VERSION ""

NS_ :

BS_:

BU_: VCU BMS DCDC OBC
VAL_TABLE_ CC2_State 1 "DC_Charge" 0 "No_DC_Charge" ;
VAL_TABLE_ DCDCOPERATINGMODE 4 "fault level-2" 3 "fault level-1" 2 "Work" 1 "Standby" 0 "Init" ;

BO_ 344 EAT_158: 8 VCU
 SG_ EAT_CHECKSUM_158 : 59|4@0+ (1,0) [0|15] ""  OBC
 SG_ EAT_ALIVE_COUNTER_158 : 61|2@0+ (1,0) [0|3] ""  OBC
 SG_ EAT_TRANS_SPEED : 39|16@0+ (0.01,0) [0|655.35] ""  OBC

BO_ 2373075255 EAT_158: 8 VCU
 SG_ EAT_CHECKSUM_158 : 59|4@0+ (1,0) [0|15] ""  OBC
 SG_ EAT_ALIVE_COUNTER_158 : 61|2@0+ (1,0) [0|3] ""  OBC
 SG_ EAT_TRANS_SPEED : 39|16@0+ (0.01,0) [0|655.35] ""  OBC

BO_ 2373075256 EAT_158: 8 VCU
 SG_ EAT_CHECKSUM_158 : 59|4@0+ (1,0) [0|15] ""  OBC
 SG_ EAT_ALIVE_COUNTER_158 : 61|2@0+ (1,0) [0|3] ""  OBC
 SG_ EAT_TRANS_SPEED : 39|16@0+ (0.01,0) [0|655.35] ""  OBC

BO_ 2373075257 EAT_158: 8 VCU
 SG_ EAT_CHECKSUM_158 : 59|4@0+ (1,0) [0|15] ""  OBC
 SG_ EAT_ALIVE_COUNTER_158 : 61|2@0+ (1,0) [0|3] ""  OBC
 SG_ EAT_TRANS_SPEED : 39|16@0+ (0.01,0) [0|655.35] ""  OBC

BO_ 2373075258 EAT_158: 8 VCU
 SG_ EAT_CHECKSUM_158 : 59|4@0+ (1,0) [0|15] ""  OBC
 SG_ EAT_ALIVE_COUNTER_158 : 61|2@0+ (1,0) [0|3] ""  OBC
 SG_ EAT_TRANS_SPEED : 39|16@0+ (0.01,0) [0|655.35] ""  OBC

BO_ 2373075259 EAT_158: 8 VCU
 SG_ EAT_CHECKSUM_158 : 59|4@0+ (1,0) [0|15] ""  OBC
 SG_ EAT_ALIVE_COUNTER_158 : 61|2@0+ (1,0) [0|3] ""  OBC
 SG_ EAT_TRANS_SPEED : 39|16@0+ (0.01,0) [0|655.35] ""  OBC

BO_ 2373075260 EAT_158: 8 VCU
 SG_ EAT_CHECKSUM_158 : 59|4@0+ (1,0) [0|15] ""  OBC
 SG_ EAT_ALIVE_COUNTER_158 : 61|2@0+ (1,0) [0|3] ""  OBC
 SG_ EAT_TRANS_SPEED : 39|16@0+ (0.01,0) [0|655.35] ""  OBC

BO_ 2373075261 EAT_158: 8 VCU
 SG_ EAT_CHECKSUM_158 : 59|4@0+ (1,0) [0|15] ""  OBC
 SG_ EAT_ALIVE_COUNTER_158 : 61|2@0+ (1,0) [0|3] ""  OBC
 SG_ EAT_TRANS_SPEED : 39|16@0+ (0.01,0) [0|655.35] ""  OBC

BO_ 2373075262 EAT_158: 8 VCU
 SG_ EAT_CHECKSUM_158 : 59|4@0+ (1,0) [0|15] ""  OBC
 SG_ EAT_ALIVE_COUNTER_158 : 61|2@0+ (1,0) [0|3] ""  OBC
 SG_ EAT_TRANS_SPEED : 39|16@0+ (0.01,0) [0|655.35] ""  OBC

BO_ 2373075263 EAT_158: 8 VCU
 SG_ EAT_CHECKSUM_158 : 59|4@0+ (1,0) [0|15] ""  OBC
 SG_ EAT_ALIVE_COUNTER_158 : 61|2@0+ (1,0) [0|3] ""  OBC
 SG_ EAT_TRANS_SPEED : 39|16@0+ (0.01,0) [0|655.35] ""  OBC

BO_ 2373075264 EAT_158: 8 VCU
 SG_ EAT_CHECKSUM_158 : 59|4@0+ (1,0) [0|15] ""  OBC
 SG_ EAT_ALIVE_COUNTER_158 : 61|2@0+ (1,0) [0|3] ""  OBC
 SG_ EAT_TRANS_SPEED : 39|16@0+ (0.01,0) [0|655.35] ""  OBC

BO_ 2373075265 EAT_158: 8 VCU
 SG_ EAT_CHECKSUM_158 : 59|4@0+ (1,0) [0|15] ""  OBC
 SG_ EAT_ALIVE_COUNTER_158 : 61|2@0+ (1,0) [0|3] ""  OBC
 SG_ EAT_TRANS_SPEED : 39|16@0+ (0.01,0) [0|655.35] ""  OBC

BO_ 2373075266 EAT_158: 8 VCU
 SG_ EAT_CHECKSUM_158 : 59|4@0+ (1,0) [0|15] ""  OBC
 SG_ EAT_ALIVE_COUNTER_158 : 61|2@0+ (1,0) [0|3] ""  OBC
 SG_ EAT_TRANS_SPEED : 39|16@0+ (0.01,0) [0|655.35] ""  OBC

BO_ 2373075267 EAT_158: 8 VCU
 SG_ EAT_CHECKSUM_158 : 59|4@0+ (1,0) [0|15] ""  OBC
 SG_ EAT_ALIVE_COUNTER_158 : 61|2@0+ (1,0) [0|3] ""  OBC
 SG_ EAT_TRANS_SPEED : 39|16@0+ (0.01,0) [0|655.35] ""  OBC

BO_ 2373075268 EAT_158: 8 VCU
 SG_ EAT_CHECKSUM_158 : 59|4@0+ (1,0) [0|15] ""  OBC
 SG_ EAT_ALIVE_COUNTER_158 : 61|2@0+ (1,0) [0|3] ""  OBC
 SG_ EAT_TRANS_SPEED : 39|16@0+ (0.01,0) [0|655.35] ""  OBC

BO_ 2373075269 EAT_158: 8 VCU
 SG_ EAT_CHECKSUM_158 : 59|4@0+ (1,0) [0|15] ""  OBC
 SG_ EAT_ALIVE_COUNTER_158 : 61|2@0+ (1,0) [0|3] ""  OBC
 SG_ EAT_TRANS_SPEED : 39|16@0+ (0.01,0) [0|655.35] ""  OBC

BO_ 2373075270 EAT_158: 8 VCU
 SG_ EAT_CHECKSUM_158 : 59|4@0+ (1,0) [0|15] ""  OBC
 SG_ EAT_ALIVE_COUNTER_158 : 61|2@0+ (1,0) [0|3] ""  OBC
 SG_ EAT_TRANS_SPEED : 39|16@0+ (0.01,0) [0|655.35] ""  OBC

BO_ 2373075271 EAT_158: 8 VCU
 SG_ EAT_CHECKSUM_158 : 59|4@0+ (1,0) [0|15] ""  OBC
 SG_ EAT_ALIVE_COUNTER_158 : 61|2@0+ (1,0) [0|3] ""  OBC
 SG_ EAT_TRANS_SPEED : 39|16@0+ (0.01,0) [0|655.35] ""  OBC

BO_ 2373075272 EAT_158: 8 VCU
 SG_ EAT_CHECKSUM_158 : 59|4@0+ (1,0) [0|15] ""  OBC
 SG_ EAT_ALIVE_COUNTER_158 : 61|2@0+ (1,0) [0|3] ""  OBC
 SG_ EAT_TRANS_SPEED : 39|16@0+ (0.01,0) [0|655.35] ""  OBC

BO_ 2373075273 EAT_158: 8 VCU
 SG_ EAT_CHECKSUM_158 : 59|4@0+ (1,0) [0|15] ""  OBC
 SG_ EAT_ALIVE_COUNTER_158 : 61|2@0+ (1,0) [0|3] ""  OBC
 SG_ EAT_TRANS_SPEED : 39|16@0+ (0.01,0) [0|655.35] ""  OBC

BO_ 2373075274 EAT_158: 8 VCU
 SG_ EAT_CHECKSUM_158 : 59|4@0+ (1,0) [0|15] ""  OBC
 SG_ EAT_ALIVE_COUNTER_158 : 61|2@0+ (1,0) [0|3] ""  OBC
 SG_ EAT_TRANS_SPEED : 39|16@0+ (0.01,0) [0|655.35] ""  OBC

BO_ 2373075275 EAT_158: 8 VCU
 SG_ EAT_CHECKSUM_158 : 59|4@0+ (1,0) [0|15] ""  OBC
 SG_ EAT_ALIVE_COUNTER_158 : 61|2@0+ (1,0) [0|3] ""  OBC
 SG_ EAT_TRANS_SPEED : 39|16@0+ (0.01,0) [0|655.35] ""  OBC

BO_ 2373075276 EAT_158: 8 VCU
 SG_ EAT_CHECKSUM_158 : 59|4@0+ (1,0) [0|15] ""  OBC
 SG_ EAT_ALIVE_COUNTER_158 : 61|2@0+ (1,0) [0|3] ""  OBC
 SG_ EAT_TRANS_SPEED : 39|16@0+ (0.01,0) [0|655.35] ""  OBC

BO_ 2373075277 EAT_158: 8 VCU
 SG_ EAT_CHECKSUM_158 : 59|4@0+ (1,0) [0|15] ""  OBC
 SG_ EAT_ALIVE_COUNTER_158 : 61|2@0+ (1,0) [0|3] ""  OBC
 SG_ EAT_TRANS_SPEED : 39|16@0+ (0.01,0) [0|655.35] ""  OBC

BO_ 2373075278 EAT_158: 8 VCU
 SG_ EAT_CHECKSUM_158 : 59|4@0+ (1,0) [0|15] ""  OBC
 SG_ EAT_ALIVE_COUNTER_158 : 61|2@0+ (1,0) [0|3] ""  OBC
 SG_ EAT_TRANS_SPEED : 39|16@0+ (0.01,0) [0|655.35] ""  OBC

BO_ 2373075279 EAT_158: 8 VCU
 SG_ EAT_CHECKSUM_158 : 59|4@0+ (1,0) [0|15] ""  OBC
 SG_ EAT_ALIVE_COUNTER_158 : 61|2@0+ (1,0) [0|3] ""  OBC
 SG_ EAT_TRANS_SPEED : 39|16@0+ (0.01,0) [0|655.35] ""  OBC

BO_ 2373075280 EAT_158: 8 VCU
 SG_ EAT_CHECKSUM_158 : 59|4@0+ (1,0) [0|15] ""  OBC
 SG_ EAT_ALIVE_COUNTER_158 : 61|2@0+ (1,0) [0|3] ""  OBC
 SG_ EAT_TRANS_SPEED : 39|16@0+ (0.01,0) [0|655.35] ""  OBC

BO_ 2373075281 EAT_158: 8 VCU
 SG_ EAT_CHECKSUM_158 : 59|4@0+ (1,0) [0|15] ""  OBC
 SG_ EAT_ALIVE_COUNTER_158 : 61|2@0+ (1,0) [0|3] ""  OBC
 SG_ EAT_TRANS_SPEED : 39|16@0+ (0.01,0) [0|655.35] ""  OBC

BO_ 2373075282 EAT_158: 8 VCU
 SG_ EAT_CHECKSUM_158 : 59|4@0+ (1,0) [0|15] ""  OBC
 SG_ EAT_ALIVE_COUNTER_158 : 61|2@0+ (1,0) [0|3] ""  OBC
 SG_ EAT_TRANS_SPEED : 39|16@0+ (0.01,0) [0|655.35] ""  OBC

BO_ 2373075283 EAT_158: 8 VCU
 SG_ EAT_CHECKSUM_158 : 59|4@0+ (1,0) [0|15] ""  OBC
 SG_ EAT_ALIVE_COUNTER_158 : 61|2@0+ (1,0) [0|3] ""  OBC
 SG_ EAT_TRANS_SPEED : 39|16@0+ (0.01,0) [0|655.35] ""  OBC

BO_ 2373075284 EAT_158: 8 VCU
 SG_ EAT_CHECKSUM_158 : 59|4@0+ (1,0) [0|15] ""  OBC
 SG_ EAT_ALIVE_COUNTER_158 : 61|2@0+ (1,0) [0|3] ""  OBC
 SG_ EAT_TRANS_SPEED : 39|16@0+ (0.01,0) [0|655.35] ""  OBC

BO_ 2373075285 EAT_158: 8 VCU
 SG_ EAT_CHECKSUM_158 : 59|4@0+ (1,0) [0|15] ""  OBC
 SG_ EAT_ALIVE_COUNTER_158 : 61|2@0+ (1,0) [0|3] ""  OBC
 SG_ EAT_TRANS_SPEED : 39|16@0+ (0.01,0) [0|655.35] ""  OBC

BO_ 2373075286 EAT_158: 8 VCU
 SG_ EAT_CHECKSUM_158 : 59|4@0+ (1,0) [0|15] ""  OBC
 SG_ EAT_ALIVE_COUNTER_158 : 61|2@0+ (1,0) [0|3] ""  OBC
 SG_ EAT_TRANS_SPEED : 39|16@0+ (0.01,0) [0|655.35] ""  OBC

BO_ 2373075287 EAT_158: 8 VCU
 SG_ EAT_CHECKSUM_158 : 59|4@0+ (1,0) [0|15] ""  OBC
 SG_ EAT_ALIVE_COUNTER_158 : 61|2@0+ (1,0) [0|3] ""  OBC
 SG_ EAT_TRANS_SPEED : 39|16@0+ (0.01,0) [0|655.35] ""  OBC

BO_ 2373075288 EAT_158: 8 VCU
 SG_ EAT_CHECKSUM_158 : 59|4@0+ (1,0) [0|15] ""  OBC
 SG_ EAT_ALIVE_COUNTER_158 : 61|2@0+ (1,0) [0|3] ""  OBC
 SG_ EAT_TRANS_SPEED : 39|16@0+ (0.01,0) [0|655.35] ""  OBC

BO_ 2373075289 EAT_158: 8 VCU
 SG_ EAT_CHECKSUM_158 : 59|4@0+ (1,0) [0|15] ""  OBC
 SG_ EAT_ALIVE_COUNTER_158 : 61|2@0+ (1,0) [0|3] ""  OBC
 SG_ EAT_TRANS_SPEED : 39|16@0+ (0.01,0) [0|655.35] ""  OBC

BO_ 2373075290 EAT_158: 8 VCU
 SG_ EAT_CHECKSUM_158 : 59|4@0+ (1,0) [0|15] ""  OBC
 SG_ EAT_ALIVE_COUNTER_158 : 61|2@0+ (1,0) [0|3] ""  OBC
 SG_ EAT_TRANS_SPEED : 39|16@0+ (0.01,0) [0|655.35] ""  OBC

BO_ 2373075291 EAT_158: 8 VCU
 SG_ EAT_CHECKSUM_158 : 59|4@0+ (1,0) [0|15] ""  OBC
 SG_ EAT_ALIVE_COUNTER_158 : 61|2@0+ (1,0) [0|3] ""  OBC
 SG_ EAT_TRANS_SPEED : 39|16@0+ (0.01,0) [0|655.35] ""  OBC

BO_ 2373075292 EAT_158: 8 VCU
 SG_ EAT_CHECKSUM_158 : 59|4@0+ (1,0) [0|15] ""  OBC
 SG_ EAT_ALIVE_COUNTER_158 : 61|2@0+ (1,0) [0|3] ""  OBC
 SG_ EAT_TRANS_SPEED : 39|16@0+ (0.01,0) [0|655.35] ""  OBC

BO_ 2373075293 EAT_158: 8 VCU
 SG_ EAT_CHECKSUM_158 : 59|4@0+ (1,0) [0|15] ""  OBC
 SG_ EAT_ALIVE_COUNTER_158 : 61|2@0+ (1,0) [0|3] ""  OBC
 SG_ EAT_TRANS_SPEED : 39|16@0+ (0.01,0) [0|655.35] ""  OBC

BO_ 2373075294 EAT_158: 8 VCU
 SG_ EAT_CHECKSUM_158 : 59|4@0+ (1,0) [0|15] ""  OBC
 SG_ EAT_ALIVE_COUNTER_158 : 61|2@0+ (1,0) [0|3] ""  OBC
 SG_ EAT_TRANS_SPEED : 39|16@0+ (0.01,0) [0|655.35] ""  OBC

BO_ 2373075295 EAT_158: 8 VCU
 SG_ EAT_CHECKSUM_158 : 59|4@0+ (1,0) [0|15] ""  OBC
 SG_ EAT_ALIVE_COUNTER_158 : 61|2@0+ (1,0) [0|3] ""  OBC
 SG_ EAT_TRANS_SPEED : 39|16@0+ (0.01,0) [0|655.35] ""  OBC

BO_ 2373075296 EAT_158: 8 VCU
 SG_ EAT_CHECKSUM_158 : 59|4@0+ (1,0) [0|15] ""  OBC
 SG_ EAT_ALIVE_COUNTER_158 : 61|2@0+ (1,0) [0|3] ""  OBC
 SG_ EAT_TRANS_SPEED : 39|16@0+ (0.01,0) [0|655.35] ""  OBC

BO_ 2373075297 EAT_158: 8 VCU
 SG_ EAT_CHECKSUM_158 : 59|4@0+ (1,0) [0|15] ""  OBC
 SG_ EAT_ALIVE_COUNTER_158 : 61|2@0+ (1,0) [0|3] ""  OBC
 SG_ EAT_TRANS_SPEED : 39|16@0+ (0.01,0) [0|655.35] ""  OBC

BO_ 2373075298 EAT_158: 8 VCU
 SG_ EAT_CHECKSUM_158 : 59|4@0+ (1,0) [0|15] ""  OBC
 SG_ EAT_ALIVE_COUNTER_158 : 61|2@0+ (1,0) [0|3] ""  OBC
 SG_ EAT_TRANS_SPEED : 39|16@0+ (0.01,0) [0|655.35] ""  OBC

BO_ 2373075299 EAT_158: 8 VCU
 SG_ EAT_CHECKSUM_158 : 59|4@0+ (1,0) [0|15] ""  OBC
 SG_ EAT_ALIVE_COUNTER_158 : 61|2@0+ (1,0) [0|3] ""  OBC
 SG_ EAT_TRANS_SPEED : 39|16@0+ (0.01,0) [0|655.35] ""  OBC

BO_ 2373075300 EAT_158: 8 VCU
 SG_ EAT_CHECKSUM_158 : 59|4@0+ (1,0) [0|15] ""  OBC
 SG_ EAT_ALIVE_COUNTER_158 : 61|2@0+ (1,0) [0|3] ""  OBC
 SG_ EAT_TRANS_SPEED : 39|16@0+ (0.01,0) [0|655.35] ""  OBC

BO_ 2373075301 EAT_158: 8 VCU
 SG_ EAT_CHECKSUM_158 : 59|4@0+ (1,0) [0|15] ""  OBC
 SG_ EAT_ALIVE_COUNTER_158 : 61|2@0+ (1,0) [0|3] ""  OBC
 SG_ EAT_TRANS_SPEED : 39|16@0+ (0.01,0) [0|655.35] ""  OBC

BO_ 2373075302 EAT_158: 8 VCU
 SG_ EAT_CHECKSUM_158 : 59|4@0+ (1,0) [0|15] ""  OBC
 SG_ EAT_ALIVE_COUNTER_158 : 61|2@0+ (1,0) [0|3] ""  OBC
 SG_ EAT_TRANS_SPEED : 39|16@0+ (0.01,0) [0|655.35] ""  OBC

BO_ 2373075303 EAT_158: 8 VCU
 SG_ EAT_CHECKSUM_158 : 59|4@0+ (1,0) [0|15] ""  OBC
 SG_ EAT_ALIVE_COUNTER_158 : 61|2@0+ (1,0) [0|3] ""  OBC
 SG_ EAT_TRANS_SPEED : 39|16@0+ (0.01,0) [0|655.35] ""  OBC

BO_ 2373075304 EAT_158: 8 VCU
 SG_ EAT_CHECKSUM_158 : 59|4@0+ (1,0) [0|15] ""  OBC
 SG_ EAT_ALIVE_COUNTER_158 : 61|2@0+ (1,0) [0|3] ""  OBC
 SG_ EAT_TRANS_SPEED : 39|16@0+ (0.01,0) [0|655.35] ""  OBC

BO_ 2373075305 EAT_158: 8 VCU
 SG_ EAT_CHECKSUM_158 : 59|4@0+ (1,0) [0|15] ""  OBC
 SG_ EAT_ALIVE_COUNTER_158 : 61|2@0+ (1,0) [0|3] ""  OBC
 SG_ EAT_TRANS_SPEED : 39|16@0+ (0.01,0) [0|655.35] ""  OBC

BO_ 2373075306 EAT_158: 8 VCU
 SG_ EAT_CHECKSUM_158 : 59|4@0+ (1,0) [0|15] ""  OBC
 SG_ EAT_ALIVE_COUNTER_158 : 61|2@0+ (1,0) [0|3] ""  OBC
 SG_ EAT_TRANS_SPEED : 39|16@0+ (0.01,0) [0|655.35] ""  OBC

BO_ 2373075307 EAT_158: 8 VCU
 SG_ EAT_CHECKSUM_158 : 59|4@0+ (1,0) [0|15] ""  OBC
 SG_ EAT_ALIVE_COUNTER_158 : 61|2@0+ (1,0) [0|3] ""  OBC
 SG_ EAT_TRANS_SPEED : 39|16@0+ (0.01,0) [0|655.35] ""  OBC

BO_ 2373075308 EAT_158: 8 VCU
 SG_ EAT_CHECKSUM_158 : 59|4@0+ (1,0) [0|15] ""  OBC
 SG_ EAT_ALIVE_COUNTER_158 : 61|2@0+ (1,0) [0|3] ""  OBC
 SG_ EAT_TRANS_SPEED : 39|16@0+ (0.01,0) [0|655.35] ""  OBC

BO_ 2373075309 EAT_158: 8 VCU
 SG_ EAT_CHECKSUM_158 : 59|4@0+ (1,0) [0|15] ""  OBC
 SG_ EAT_ALIVE_COUNTER_158 : 61|2@0+ (1,0) [0|3] ""  OBC
 SG_ EAT_TRANS_SPEED : 39|16@0+ (0.01,0) [0|655.35] ""  OBC

BO_ 2373075310 EAT_158: 8 VCU
 SG_ EAT_CHECKSUM_158 : 59|4@0+ (1,0) [0|15] ""  OBC
 SG_ EAT_ALIVE_COUNTER_158 : 61|2@0+ (1,0) [0|3] ""  OBC
 SG_ EAT_TRANS_SPEED : 39|16@0+ (0.01,0) [0|655.35] ""  OBC

BO_ 2373075311 EAT_158: 8 VCU
 SG_ EAT_CHECKSUM_158 : 59|4@0+ (1,0) [0|15] ""  OBC
 SG_ EAT_ALIVE_COUNTER_158 : 61|2@0+ (1,0) [0|3] ""  OBC
 SG_ EAT_TRANS_SPEED : 39|16@0+ (0.01,0) [0|655.35] ""  OBC

BO_ 2373075312 EAT_158: 8 VCU
 SG_ EAT_CHECKSUM_158 : 59|4@0+ (1,0) [0|15] ""  OBC
 SG_ EAT_ALIVE_COUNTER_158 : 61|2@0+ (1,0) [0|3] ""  OBC
 SG_ EAT_TRANS_SPEED : 39|16@0+ (0.01,0) [0|655.35] ""  OBC

BO_ 2373075313 EAT_158: 8 VCU
 SG_ EAT_CHECKSUM_158 : 59|4@0+ (1,0) [0|15] ""  OBC
 SG_ EAT_ALIVE_COUNTER_158 : 61|2@0+ (1,0) [0|3] ""  OBC
 SG_ EAT_TRANS_SPEED : 39|16@0+ (0.01,0) [0|655.35] ""  OBC

BO_ 2373075314 EAT_158: 8 VCU
 SG_ EAT_CHECKSUM_158 : 59|4@0+ (1,0) [0|15] ""  OBC
 SG_ EAT_ALIVE_COUNTER_158 : 61|2@0+ (1,0) [0|3] ""  OBC
 SG_ EAT_TRANS_SPEED : 39|16@0+ (0.01,0) [0|655.35] ""  OBC

BO_ 2373075315 EAT_158: 8 VCU
 SG_ EAT_CHECKSUM_158 : 59|4@0+ (1,0) [0|15] ""  OBC
 SG_ EAT_ALIVE_COUNTER_158 : 61|2@0+ (1,0) [0|3] ""  OBC
 SG_ EAT_TRANS_SPEED : 39|16@0+ (0.01,0) [0|655.35] ""  OBC

BO_ 2373075316 EAT_158: 8 VCU
 SG_ EAT_CHECKSUM_158 : 59|4@0+ (1,0) [0|15] ""  OBC
 SG_ EAT_ALIVE_COUNTER_158 : 61|2@0+ (1,0) [0|3] ""  OBC
 SG_ EAT_TRANS_SPEED : 39|16@0+ (0.01,0) [0|655.35] ""  OBC

BO_ 2373075317 EAT_158: 8 VCU
 SG_ EAT_CHECKSUM_158 : 59|4@0+ (1,0) [0|15] ""  OBC
 SG_ EAT_ALIVE_COUNTER_158 : 61|2@0+ (1,0) [0|3] ""  OBC
 SG_ EAT_TRANS_SPEED : 39|16@0+ (0.01,0) [0|655.35] ""  OBC

BO_ 2373075318 EAT_158: 8 VCU
 SG_ EAT_CHECKSUM_158 : 59|4@0+ (1,0) [0|15] ""  OBC
 SG_ EAT_ALIVE_COUNTER_158 : 61|2@0+ (1,0) [0|3] ""  OBC
 SG_ EAT_TRANS_SPEED : 39|16@0+ (0.01,0) [0|655.35] ""  OBC

BO_ 2373075319 EAT_158: 8 VCU
 SG_ EAT_CHECKSUM_158 : 59|4@0+ (1,0) [0|15] ""  OBC
 SG_ EAT_ALIVE_COUNTER_158 : 61|2@0+ (1,0) [0|3] ""  OBC
 SG_ EAT_TRANS_SPEED : 39|16@0+ (0.01,0) [0|655.35] ""  OBC

BO_ 2373075320 EAT_158: 8 VCU
 SG_ EAT_CHECKSUM_158 : 59|4@0+ (1,0) [0|15] ""  OBC
 SG_ EAT_ALIVE_COUNTER_158 : 61|2@0+ (1,0) [0|3] ""  OBC
 SG_ EAT_TRANS_SPEED : 39|16@0+ (0.01,0) [0|655.35] ""  OBC

BO_ 2373075321 EAT_158: 8 VCU
 SG_ EAT_CHECKSUM_158 : 59|4@0+ (1,0) [0|15] ""  OBC
 SG_ EAT_ALIVE_COUNTER_158 : 61|2@0+ (1,0) [0|3] ""  OBC
 SG_ EAT_TRANS_SPEED : 39|16@0+ (0.01,0) [0|655.35] ""  OBC

BO_ 2373075322 EAT_158: 8 VCU
 SG_ EAT_CHECKSUM_158 : 59|4@0+ (1,0) [0|15] ""  OBC
 SG_ EAT_ALIVE_COUNTER_158 : 61|2@0+ (1,0) [0|3] ""  OBC
 SG_ EAT_TRANS_SPEED : 39|16@0+ (0.01,0) [0|655.35] ""  OBC

BO_ 2373075323 EAT_158: 8 VCU
 SG_ EAT_CHECKSUM_158 : 59|4@0+ (1,0) [0|15] ""  OBC
 SG_ EAT_ALIVE_COUNTER_158 : 61|2@0+ (1,0) [0|3] ""  OBC
 SG_ EAT_TRANS_SPEED : 39|16@0+ (0.01,0) [0|655.35] ""  OBC

BO_ 2373075324 EAT_158: 8 VCU
 SG_ EAT_CHECKSUM_158 : 59|4@0+ (1,0) [0|15] ""  OBC
 SG_ EAT_ALIVE_COUNTER_158 : 61|2@0+ (1,0) [0|3] ""  OBC
 SG_ EAT_TRANS_SPEED : 39|16@0+ (0.01,0) [0|655.35] ""  OBC

BO_ 2373075325 EAT_158: 8 VCU
 SG_ EAT_CHECKSUM_158 : 59|4@0+ (1,0) [0|15] ""  OBC
 SG_ EAT_ALIVE_COUNTER_158 : 61|2@0+ (1,0) [0|3] ""  OBC
 SG_ EAT_TRANS_SPEED : 39|16@0+ (0.01,0) [0|655.35] ""  OBC

BO_ 2373075326 EAT_158: 8 VCU
 SG_ EAT_CHECKSUM_158 : 59|4@0+ (1,0) [0|15] ""  OBC
 SG_ EAT_ALIVE_COUNTER_158 : 61|2@0+ (1,0) [0|3] ""  OBC
 SG_ EAT_TRANS_SPEED : 39|16@0+ (0.01,0) [0|655.35] ""  OBC

BO_ 2373075327 EAT_158: 8 VCU
 SG_ EAT_CHECKSUM_158 : 59|4@0+ (1,0) [0|15] ""  OBC
 SG_ EAT_ALIVE_COUNTER_158 : 61|2@0+ (1,0) [0|3] ""  OBC
 SG_ EAT_TRANS_SPEED : 39|16@0+ (0.01,0) [0|655.35] ""  OBC

BO_ 2373075328 EAT_158: 8 VCU
 SG_ EAT_CHECKSUM_158 : 59|4@0+ (1,0) [0|15] ""  OBC
 SG_ EAT_ALIVE_COUNTER_158 : 61|2@0+ (1,0) [0|3] ""  OBC
 SG_ EAT_TRANS_SPEED : 39|16@0+ (0.01,0) [0|655.35] ""  OBC

BO_ 2373075329 EAT_158: 8 VCU
 SG_ EAT_CHECKSUM_158 : 59|4@0+ (1,0) [0|15] ""  OBC
 SG_ EAT_ALIVE_COUNTER_158 : 61|2@0+ (1,0) [0|3] ""  OBC
 SG_ EAT_TRANS_SPEED : 39|16@0+ (0.01,0) [0|655.35] ""  OBC

BO_ 2373075330 EAT_158: 8 VCU
 SG_ EAT_CHECKSUM_158 : 59|4@0+ (1,0) [0|15] ""  OBC
 SG_ EAT_ALIVE_COUNTER_158 : 61|2@0+ (1,0) [0|3] ""  OBC
 SG_ EAT_TRANS_SPEED : 39|16@0+ (0.01,0) [0|655.35] ""  OBC

BO_ 2373075331 EAT_158: 8 VCU
 SG_ EAT_CHECKSUM_158 : 59|4@0+ (1,0) [0|15] ""  OBC
 SG_ EAT_ALIVE_COUNTER_158 : 61|2@0+ (1,0) [0|3] ""  OBC
 SG_ EAT_TRANS_SPEED : 39|16@0+ (0.01,0) [0|655.35] ""  OBC

BO_ 2373075332 EAT_158: 8 VCU
 SG_ EAT_CHECKSUM_158 : 59|4@0+ (1,0) [0|15] ""  OBC
 SG_ EAT_ALIVE_COUNTER_158 : 61|2@0+ (1,0) [0|3] ""  OBC
 SG_ EAT_TRANS_SPEED : 39|16@0+ (0.01,0) [0|655.35] ""  OBC

BO_ 2373075333 EAT_158: 8 VCU
 SG_ EAT_CHECKSUM_158 : 59|4@0+ (1,0) [0|15] ""  OBC
 SG_ EAT_ALIVE_COUNTER_158 : 61|2@0+ (1,0) [0|3] ""  OBC
 SG_ EAT_TRANS_SPEED : 39|16@0+ (0.01,0) [0|655.35] ""  OBC

BO_ 2373075334 EAT_158: 8 VCU
 SG_ EAT_CHECKSUM_158 : 59|4@0+ (1,0) [0|15] ""  OBC
 SG_ EAT_ALIVE_COUNTER_158 : 61|2@0+ (1,0) [0|3] ""  OBC
 SG_ EAT_TRANS_SPEED : 39|16@0+ (0.01,0) [0|655.35] ""  OBC

BO_ 2373075335 EAT_158: 8 VCU
 SG_ EAT_CHECKSUM_158 : 59|4@0+ (1,0) [0|15] ""  OBC
 SG_ EAT_ALIVE_COUNTER_158 : 61|2@0+ (1,0) [0|3] ""  OBC
 SG_ EAT_TRANS_SPEED : 39|16@0+ (0.01,0) [0|655.35] ""  OBC

BO_ 2373075336 EAT_158: 8 VCU
 SG_ EAT_CHECKSUM_158 : 59|4@0+ (1,0) [0|15] ""  OBC
 SG_ EAT_ALIVE_COUNTER_158 : 61|2@0+ (1,0) [0|3] ""  OBC
 SG_ EAT_TRANS_SPEED : 39|16@0+ (0.01,0) [0|655.35] ""  OBC

BO_ 2373075337 EAT_158: 8 VCU
 SG_ EAT_CHECKSUM_158 : 59|4@0+ (1,0) [0|15] ""  OBC
 SG_ EAT_ALIVE_COUNTER_158 : 61|2@0+ (1,0) [0|3] ""  OBC
 SG_ EAT_TRANS_SPEED : 39|16@0+ (0.01,0) [0|655.35] ""  OBC

BO_ 2373075338 EAT_158: 8 VCU
 SG_ EAT_CHECKSUM_158 : 59|4@0+ (1,0) [0|15] ""  OBC
 SG_ EAT_ALIVE_COUNTER_158 : 61|2@0+ (1,0) [0|3] ""  OBC
 SG_ EAT_TRANS_SPEED : 39|16@0+ (0.01,0) [0|655.35] ""  OBC

BO_ 2373075339 EAT_158: 8 VCU
 SG_ EAT_CHECKSUM_158 : 59|4@0+ (1,0) [0|15] ""  OBC
 SG_ EAT_ALIVE_COUNTER_158 : 61|2@0+ (1,0) [0|3] ""  OBC
 SG_ EAT_TRANS_SPEED : 39|16@0+ (0.01,0) [0|655.35] ""  OBC

BO_ 2373075340 EAT_158: 8 VCU
 SG_ EAT_CHECKSUM_158 : 59|4@0+ (1,0) [0|15] ""  OBC
 SG_ EAT_ALIVE_COUNTER_158 : 61|2@0+ (1,0) [0|3] ""  OBC
 SG_ EAT_TRANS_SPEED : 39|16@0+ (0.01,0) [0|655.35] ""  OBC

BO_ 2373075341 EAT_158: 8 VCU
 SG_ EAT_CHECKSUM_158 : 59|4@0+ (1,0) [0|15] ""  OBC
 SG_ EAT_ALIVE_COUNTER_158 : 61|2@0+ (1,0) [0|3] ""  OBC
 SG_ EAT_TRANS_SPEED : 39|16@0+ (0.01,0) [0|655.35] ""  OBC

BO_ 2373075342 EAT_158: 8 VCU
 SG_ EAT_CHECKSUM_158 : 59|4@0+ (1,0) [0|15] ""  OBC
 SG_ EAT_ALIVE_COUNTER_158 : 61|2@0+ (1,0) [0|3] ""  OBC
 SG_ EAT_TRANS_SPEED : 39|16@0+ (0.01,0) [0|655.35] ""  OBC

BO_ 2373075343 EAT_158: 8 VCU
 SG_ EAT_CHECKSUM_158 : 59|4@0+ (1,0) [0|15] ""  OBC
 SG_ EAT_ALIVE_COUNTER_158 : 61|2@0+ (1,0) [0|3] ""  OBC
 SG_ EAT_TRANS_SPEED : 39|16@0+ (0.01,0) [0|655.35] ""  OBC

BO_ 2373075344 EAT_158: 8 VCU
 SG_ EAT_CHECKSUM_158 : 59|4@0+ (1,0) [0|15] ""  OBC
 SG_ EAT_ALIVE_COUNTER_158 : 61|2@0+ (1,0) [0|3] ""  OBC
 SG_ EAT_TRANS_SPEED : 39|16@0+ (0.01,0) [0|655.35] ""  OBC

BO_ 2373075345 EAT_158: 8 VCU
 SG_ EAT_CHECKSUM_158 : 59|4@0+ (1,0) [0|15] ""  OBC
 SG_ EAT_ALIVE_COUNTER_158 : 61|2@0+ (1,0) [0|3] ""  OBC
 SG_ EAT_TRANS_SPEED : 39|16@0+ (0.01,0) [0|655.35] ""  OBC

BO_ 2373075346 EAT_158: 8 VCU
 SG_ EAT_CHECKSUM_158 : 59|4@0+ (1,0) [0|15] ""  OBC
 SG_ EAT_ALIVE_COUNTER_158 : 61|2@0+ (1,0) [0|3] ""  OBC
 SG_ EAT_TRANS_SPEED : 39|16@0+ (0.01,0) [0|655.35] ""  OBC

BO_ 2373075347 EAT_158: 8 VCU
 SG_ EAT_CHECKSUM_158 : 59|4@0+ (1,0) [0|15] ""  OBC
 SG_ EAT_ALIVE_COUNTER_158 : 61|2@0+ (1,0) [0|3] ""  OBC
 SG_ EAT_TRANS_SPEED : 39|16@0+ (0.01,0) [0|655.35] ""  OBC

BO_ 2373075348 EAT_158: 8 VCU
 SG_ EAT_CHECKSUM_158 : 59|4@0+ (1,0) [0|15] ""  OBC
 SG_ EAT_ALIVE_COUNTER_158 : 61|2@0+ (1,0) [0|3] ""  OBC
 SG_ EAT_TRANS_SPEED : 39|16@0+ (0.01,0) [0|655.35] ""  OBC

BO_ 2373075349 EAT_158: 8 VCU
 SG_ EAT_CHECKSUM_158 : 59|4@0+ (1,0) [0|15] ""  OBC
 SG_ EAT_ALIVE_COUNTER_158 : 61|2@0+ (1,0) [0|3] ""  OBC
 SG_ EAT_TRANS_SPEED : 39|16@0+ (0.01,0) [0|655.35] ""  OBC

BO_ 2373075350 EAT_158: 8 VCU
 SG_ EAT_CHECKSUM_158 : 59|4@0+ (1,0) [0|15] ""  OBC
 SG_ EAT_ALIVE_COUNTER_158 : 61|2@0+ (1,0) [0|3] ""  OBC
 SG_ EAT_TRANS_SPEED : 39|16@0+ (0.01,0) [0|655.35] ""  OBC

BO_ 2373075351 EAT_158: 8 VCU
 SG_ EAT_CHECKSUM_158 : 59|4@0+ (1,0) [0|15] ""  OBC
 SG_ EAT_ALIVE_COUNTER_158 : 61|2@0+ (1,0) [0|3] ""  OBC
 SG_ EAT_TRANS_SPEED : 39|16@0+ (0.01,0) [0|655.35] ""  OBC

BO_ 2373075352 EAT_158: 8 VCU
 SG_ EAT_CHECKSUM_158 : 59|4@0+ (1,0) [0|15] ""  OBC
 SG_ EAT_ALIVE_COUNTER_158 : 61|2@0+ (1,0) [0|3] ""  OBC
 SG_ EAT_TRANS_SPEED : 39|16@0+ (0.01,0) [0|655.35] ""  OBC

BO_ 2373075353 EAT_158: 8 VCU
 SG_ EAT_CHECKSUM_158 : 59|4@0+ (1,0) [0|15] ""  OBC
 SG_ EAT_ALIVE_COUNTER_158 : 61|2@0+ (1,0) [0|3] ""  OBC
 SG_ EAT_TRANS_SPEED : 39|16@0+ (0.01,0) [0|655.35] ""  OBC

BO_ 2373075354 EAT_158: 8 VCU
 SG_ EAT_CHECKSUM_158 : 59|4@0+ (1,0) [0|15] ""  OBC
 SG_ EAT_ALIVE_COUNTER_158 : 61|2@0+ (1,0) [0|3] ""  OBC
 SG_ EAT_TRANS_SPEED : 39|16@0+ (0.01,0) [0|655.35] ""  OBC

BO_ 2373075355 EAT_158: 8 VCU
 SG_ EAT_CHECKSUM_158 : 59|4@0+ (1,0) [0|15] ""  OBC
 SG_ EAT_ALIVE_COUNTER_158 : 61|2@0+ (1,0) [0|3] ""  OBC
 SG_ EAT_TRANS_SPEED : 39|16@0+ (0.01,0) [0|655.35] ""  OBC

BO_ 2373075356 EAT_158: 8 VCU
 SG_ EAT_CHECKSUM_158 : 59|4@0+ (1,0) [0|15] ""  OBC
 SG_ EAT_ALIVE_COUNTER_158 : 61|2@0+ (1,0) [0|3] ""  OBC
 SG_ EAT_TRANS_SPEED : 39|16@0+ (0.01,0) [0|655.35] ""  OBC

BO_ 2373075357 EAT_158: 8 VCU
 SG_ EAT_CHECKSUM_158 : 59|4@0+ (1,0) [0|15] ""  OBC
 SG_ EAT_ALIVE_COUNTER_158 : 61|2@0+ (1,0) [0|3] ""  OBC
 SG_ EAT_TRANS_SPEED : 39|16@0+ (0.01,0) [0|655.35] ""  OBC

BO_ 2373075358 EAT_158: 8 VCU
 SG_ EAT_CHECKSUM_158 : 59|4@0+ (1,0) [0|15] ""  OBC
 SG_ EAT_ALIVE_COUNTER_158 : 61|2@0+ (1,0) [0|3] ""  OBC
 SG_ EAT_TRANS_SPEED : 39|16@0+ (0.01,0) [0|655.35] ""  OBC

BO_ 2373075359 EAT_158: 8 VCU
 SG_ EAT_CHECKSUM_158 : 59|4@0+ (1,0) [0|15] ""  OBC
 SG_ EAT_ALIVE_COUNTER_158 : 61|2@0+ (1,0) [0|3] ""  OBC
 SG_ EAT_TRANS_SPEED : 39|16@0+ (0.01,0) [0|655.35] ""  OBC

BO_ 2373075360 EAT_158: 8 VCU
 SG_ EAT_CHECKSUM_158 : 59|4@0+ (1,0) [0|15] ""  OBC
 SG_ EAT_ALIVE_COUNTER_158 : 61|2@0+ (1,0) [0|3] ""  OBC
 SG_ EAT_TRANS_SPEED : 39|16@0+ (0.01,0) [0|655.35] ""  OBC

BO_ 2373075361 EAT_158: 8 VCU
 SG_ EAT_CHECKSUM_158 : 59|4@0+ (1,0) [0|15] ""  OBC
 SG_ EAT_ALIVE_COUNTER_158 : 61|2@0+ (1,0) [0|3] ""  OBC
 SG_ EAT_TRANS_SPEED : 39|16@0+ (0.01,0) [0|655.35] ""  OBC

BO_ 2373075362 EAT_158: 8 VCU
 SG_ EAT_CHECKSUM_158 : 59|4@0+ (1,0) [0|15] ""  OBC
 SG_ EAT_ALIVE_COUNTER_158 : 61|2@0+ (1,0) [0|3] ""  OBC
 SG_ EAT_TRANS_SPEED : 39|16@0+ (0.01,0) [0|655.35] ""  OBC

BO_ 2373075363 EAT_158: 8 VCU
 SG_ EAT_CHECKSUM_158 : 59|4@0+ (1,0) [0|15] ""  OBC
 SG_ EAT_ALIVE_COUNTER_158 : 61|2@0+ (1,0) [0|3] ""  OBC
 SG_ EAT_TRANS_SPEED : 39|16@0+ (0.01,0) [0|655.35] ""  OBC

BO_ 2373075364 EAT_158: 8 VCU
 SG_ EAT_CHECKSUM_158 : 59|4@0+ (1,0) [0|15] ""  OBC
 SG_ EAT_ALIVE_COUNTER_158 : 61|2@0+ (1,0) [0|3] ""  OBC
 SG_ EAT_TRANS_SPEED : 39|16@0+ (0.01,0) [0|655.35] ""  OBC

BO_ 2373075365 EAT_158: 8 VCU
 SG_ EAT_CHECKSUM_158 : 59|4@0+ (1,0) [0|15] ""  OBC
 SG_ EAT_ALIVE_COUNTER_158 : 61|2@0+ (1,0) [0|3] ""  OBC
 SG_ EAT_TRANS_SPEED : 39|16@0+ (0.01,0) [0|655.35] ""  OBC

BO_ 2373075366 EAT_158: 8 VCU
 SG_ EAT_CHECKSUM_158 : 59|4@0+ (1,0) [0|15] ""  OBC
 SG_ EAT_ALIVE_COUNTER_158 : 61|2@0+ (1,0) [0|3] ""  OBC
 SG_ EAT_TRANS_SPEED : 39|16@0+ (0.01,0) [0|655.35] ""  OBC

BO_ 2373075367 EAT_158: 8 VCU
 SG_ EAT_CHECKSUM_158 : 59|4@0+ (1,0) [0|15] ""  OBC
 SG_ EAT_ALIVE_COUNTER_158 : 61|2@0+ (1,0) [0|3] ""  OBC
 SG_ EAT_TRANS_SPEED : 39|16@0+ (0.01,0) [0|655.35] ""  OBC

BO_ 2373075368 EAT_158: 8 VCU
 SG_ EAT_CHECKSUM_158 : 59|4@0+ (1,0) [0|15] ""  OBC
 SG_ EAT_ALIVE_COUNTER_158 : 61|2@0+ (1,0) [0|3] ""  OBC
 SG_ EAT_TRANS_SPEED : 39|16@0+ (0.01,0) [0|655.35] ""  OBC

BO_ 2373075369 EAT_158: 8 VCU
 SG_ EAT_CHECKSUM_158 : 59|4@0+ (1,0) [0|15] ""  OBC
 SG_ EAT_ALIVE_COUNTER_158 : 61|2@0+ (1,0) [0|3] ""  OBC
 SG_ EAT_TRANS_SPEED : 39|16@0+ (0.01,0) [0|655.35] ""  OBC

BO_ 2373075370 EAT_158: 8 VCU
 SG_ EAT_CHECKSUM_158 : 59|4@0+ (1,0) [0|15] ""  OBC
 SG_ EAT_ALIVE_COUNTER_158 : 61|2@0+ (1,0) [0|3] ""  OBC
 SG_ EAT_TRANS_SPEED : 39|16@0+ (0.01,0) [0|655.35] ""  OBC

BO_ 2373075371 EAT_158: 8 VCU
 SG_ EAT_CHECKSUM_158 : 59|4@0+ (1,0) [0|15] ""  OBC
 SG_ EAT_ALIVE_COUNTER_158 : 61|2@0+ (1,0) [0|3] ""  OBC
 SG_ EAT_TRANS_SPEED : 39|16@0+ (0.01,0) [0|655.35] ""  OBC

BO_ 2373075372 EAT_158: 8 VCU
 SG_ EAT_CHECKSUM_158 : 59|4@0+ (1,0) [0|15] ""  OBC
 SG_ EAT_ALIVE_COUNTER_158 : 61|2@0+ (1,0) [0|3] ""  OBC
 SG_ EAT_TRANS_SPEED : 39|16@0+ (0.01,0) [0|655.35] ""  OBC

BO_ 2373075373 EAT_158: 8 VCU
 SG_ EAT_CHECKSUM_158 : 59|4@0+ (1,0) [0|15] ""  OBC
 SG_ EAT_ALIVE_COUNTER_158 : 61|2@0+ (1,0) [0|3] ""  OBC
 SG_ EAT_TRANS_SPEED : 39|16@0+ (0.01,0) [0|655.35] ""  OBC

BO_ 2373075374 EAT_158: 8 VCU
 SG_ EAT_CHECKSUM_158 : 59|4@0+ (1,0) [0|15] ""  OBC
 SG_ EAT_ALIVE_COUNTER_158 : 61|2@0+ (1,0) [0|3] ""  OBC
 SG_ EAT_TRANS_SPEED : 39|16@0+ (0.01,0) [0|655.35] ""  OBC

BO_ 2373075375 EAT_158: 8 VCU
 SG_ EAT_CHECKSUM_158 : 59|4@0+ (1,0) [0|15] ""  OBC
 SG_ EAT_ALIVE_COUNTER_158 : 61|2@0+ (1,0) [0|3] ""  OBC
 SG_ EAT_TRANS_SPEED : 39|16@0+ (0.01,0) [0|655.35] ""  OBC

BO_ 2373075376 EAT_158: 8 VCU
 SG_ EAT_CHECKSUM_158 : 59|4@0+ (1,0) [0|15] ""  OBC
 SG_ EAT_ALIVE_COUNTER_158 : 61|2@0+ (1,0) [0|3] ""  OBC
 SG_ EAT_TRANS_SPEED : 39|16@0+ (0.01,0) [0|655.35] ""  OBC

BO_ 2373075377 EAT_158: 8 VCU
 SG_ EAT_CHECKSUM_158 : 59|4@0+ (1,0) [0|15] ""  OBC
 SG_ EAT_ALIVE_COUNTER_158 : 61|2@0+ (1,0) [0|3] ""  OBC
 SG_ EAT_TRANS_SPEED : 39|16@0+ (0.01,0) [0|655.35] ""  OBC

BO_ 2373075378 EAT_158: 8 VCU
 SG_ EAT_CHECKSUM_158 : 59|4@0+ (1,0) [0|15] ""  OBC
 SG_ EAT_ALIVE_COUNTER_158 : 61|2@0+ (1,0) [0|3] ""  OBC
 SG_ EAT_TRANS_SPEED : 39|16@0+ (0.01,0) [0|655.35] ""  OBC

BO_ 2373075379 EAT_158: 8 VCU
 SG_ EAT_CHECKSUM_158 : 59|4@0+ (1,0) [0|15] ""  OBC
 SG_ EAT_ALIVE_COUNTER_158 : 61|2@0+ (1,0) [0|3] ""  OBC
 SG_ EAT_TRANS_SPEED : 39|16@0+ (0.01,0) [0|655.35] ""  OBC

BO_ 2373075380 EAT_158: 8 VCU
 SG_ EAT_CHECKSUM_158 : 59|4@0+ (1,0) [0|15] ""  OBC
 SG_ EAT_ALIVE_COUNTER_158 : 61|2@0+ (1,0) [0|3] ""  OBC
 SG_ EAT_TRANS_SPEED : 39|16@0+ (0.01,0) [0|655.35] ""  OBC

BO_ 2373075381 EAT_158: 8 VCU
 SG_ EAT_CHECKSUM_158 : 59|4@0+ (1,0) [0|15] ""  OBC
 SG_ EAT_ALIVE_COUNTER_158 : 61|2@0+ (1,0) [0|3] ""  OBC
 SG_ EAT_TRANS_SPEED : 39|16@0+ (0.01,0) [0|655.35] ""  OBC

BO_ 2373075382 EAT_158: 8 VCU
 SG_ EAT_CHECKSUM_158 : 59|4@0+ (1,0) [0|15] ""  OBC
 SG_ EAT_ALIVE_COUNTER_158 : 61|2@0+ (1,0) [0|3] ""  OBC
 SG_ EAT_TRANS_SPEED : 39|16@0+ (0.01,0) [0|655.35] ""  OBC

BO_ 2373075383 EAT_158: 8 VCU
 SG_ EAT_CHECKSUM_158 : 59|4@0+ (1,0) [0|15] ""  OBC
 SG_ EAT_ALIVE_COUNTER_158 : 61|2@0+ (1,0) [0|3] ""  OBC
 SG_ EAT_TRANS_SPEED : 39|16@0+ (0.01,0) [0|655.35] ""  OBC

BO_ 2373075384 EAT_158: 8 VCU
 SG_ EAT_CHECKSUM_158 : 59|4@0+ (1,0) [0|15] ""  OBC
 SG_ EAT_ALIVE_COUNTER_158 : 61|2@0+ (1,0) [0|3] ""  OBC
 SG_ EAT_TRANS_SPEED : 39|16@0+ (0.01,0) [0|655.35] ""  OBC

BO_ 2373075385 EAT_158: 8 VCU
 SG_ EAT_CHECKSUM_158 : 59|4@0+ (1,0) [0|15] ""  OBC
 SG_ EAT_ALIVE_COUNTER_158 : 61|2@0+ (1,0) [0|3] ""  OBC
 SG_ EAT_TRANS_SPEED : 39|16@0+ (0.01,0) [0|655.35] ""  OBC

BO_ 2373075386 EAT_158: 8 VCU
 SG_ EAT_CHECKSUM_158 : 59|4@0+ (1,0) [0|15] ""  OBC
 SG_ EAT_ALIVE_COUNTER_158 : 61|2@0+ (1,0) [0|3] ""  OBC
 SG_ EAT_TRANS_SPEED : 39|16@0+ (0.01,0) [0|655.35] ""  OBC

BO_ 2373075387 EAT_158: 8 VCU
 SG_ EAT_CHECKSUM_158 : 59|4@0+ (1,0) [0|15] ""  OBC
 SG_ EAT_ALIVE_COUNTER_158 : 61|2@0+ (1,0) [0|3] ""  OBC
 SG_ EAT_TRANS_SPEED : 39|16@0+ (0.01,0) [0|655.35] ""  OBC

BO_ 2373075388 EAT_158: 8 VCU
 SG_ EAT_CHECKSUM_158 : 59|4@0+ (1,0) [0|15] ""  OBC
 SG_ EAT_ALIVE_COUNTER_158 : 61|2@0+ (1,0) [0|3] ""  OBC
 SG_ EAT_TRANS_SPEED : 39|16@0+ (0.01,0) [0|655.35] ""  OBC

BO_ 2373075389 EAT_158: 8 VCU
 SG_ EAT_CHECKSUM_158 : 59|4@0+ (1,0) [0|15] ""  OBC
 SG_ EAT_ALIVE_COUNTER_158 : 61|2@0+ (1,0) [0|3] ""  OBC
 SG_ EAT_TRANS_SPEED : 39|16@0+ (0.01,0) [0|655.35] ""  OBC

BO_ 2373075390 EAT_158: 8 VCU
 SG_ EAT_CHECKSUM_158 : 59|4@0+ (1,0) [0|15] ""  OBC
 SG_ EAT_ALIVE_COUNTER_158 : 61|2@0+ (1,0) [0|3] ""  OBC
 SG_ EAT_TRANS_SPEED : 39|16@0+ (0.01,0) [0|655.35] ""  OBC

BO_ 2373075391 EAT_158: 8 VCU
 SG_ EAT_CHECKSUM_158 : 59|4@0+ (1,0) [0|15] ""  OBC
 SG_ EAT_ALIVE_COUNTER_158 : 61|2@0+ (1,0) [0|3] ""  OBC
 SG_ EAT_TRANS_SPEED : 39|16@0+ (0.01,0) [0|655.35] ""  OBC

BO_ 2373075392 EAT_158: 8 VCU
 SG_ EAT_CHECKSUM_158 : 59|4@0+ (1,0) [0|15] ""  OBC
 SG_ EAT_ALIVE_COUNTER_158 : 61|2@0+ (1,0) [0|3] ""  OBC
 SG_ EAT_TRANS_SPEED : 39|16@0+ (0.01,0) [0|655.35] ""  OBC

BO_ 2373075393 EAT_158: 8 VCU
 SG_ EAT_CHECKSUM_158 : 59|4@0+ (1,0) [0|15] ""  OBC
 SG_ EAT_ALIVE_COUNTER_158 : 61|2@0+ (1,0) [0|3] ""  OBC
 SG_ EAT_TRANS_SPEED : 39|16@0+ (0.01,0) [0|655.35] ""  OBC

BO_ 2373075394 EAT_158: 8 VCU
 SG_ EAT_CHECKSUM_158 : 59|4@0+ (1,0) [0|15] ""  OBC
 SG_ EAT_ALIVE_COUNTER_158 : 61|2@0+ (1,0) [0|3] ""  OBC
 SG_ EAT_TRANS_SPEED : 39|16@0+ (0.01,0) [0|655.35] ""  OBC

BO_ 2373075395 EAT_158: 8 VCU
 SG_ EAT_CHECKSUM_158 : 59|4@0+ (1,0) [0|15] ""  OBC
 SG_ EAT_ALIVE_COUNTER_158 : 61|2@0+ (1,0) [0|3] ""  OBC
 SG_ EAT_TRANS_SPEED : 39|16@0+ (0.01,0) [0|655.35] ""  OBC

BO_ 2373075396 EAT_158: 8 VCU
 SG_ EAT_CHECKSUM_158 : 59|4@0+ (1,0) [0|15] ""  OBC
 SG_ EAT_ALIVE_COUNTER_158 : 61|2@0+ (1,0) [0|3] ""  OBC
 SG_ EAT_TRANS_SPEED : 39|16@0+ (0.01,0) [0|655.35] ""  OBC

BO_ 2373075397 EAT_158: 8 VCU
 SG_ EAT_CHECKSUM_158 : 59|4@0+ (1,0) [0|15] ""  OBC
 SG_ EAT_ALIVE_COUNTER_158 : 61|2@0+ (1,0) [0|3] ""  OBC
 SG_ EAT_TRANS_SPEED : 39|16@0+ (0.01,0) [0|655.35] ""  OBC

BO_ 2373075398 EAT_158: 8 VCU
 SG_ EAT_CHECKSUM_158 : 59|4@0+ (1,0) [0|15] ""  OBC
 SG_ EAT_ALIVE_COUNTER_158 : 61|2@0+ (1,0) [0|3] ""  OBC
 SG_ EAT_TRANS_SPEED : 39|16@0+ (0.01,0) [0|655.35] ""  OBC

BO_ 2373075399 EAT_158: 8 VCU
 SG_ EAT_CHECKSUM_158 : 59|4@0+ (1,0) [0|15] ""  OBC
 SG_ EAT_ALIVE_COUNTER_158 : 61|2@0+ (1,0) [0|3] ""  OBC
 SG_ EAT_TRANS_SPEED : 39|16@0+ (0.01,0) [0|655.35] ""  OBC

BO_ 2373075400 EAT_158: 8 VCU
 SG_ EAT_CHECKSUM_158 : 59|4@0+ (1,0) [0|15] ""  OBC
 SG_ EAT_ALIVE_COUNTER_158 : 61|2@0+ (1,0) [0|3] ""  OBC
 SG_ EAT_TRANS_SPEED : 39|16@0+ (0.01,0) [0|655.35] ""  OBC

BO_ 2373075401 EAT_158: 8 VCU
 SG_ EAT_CHECKSUM_158 : 59|4@0+ (1,0) [0|15] ""  OBC
 SG_ EAT_ALIVE_COUNTER_158 : 61|2@0+ (1,0) [0|3] ""  OBC
 SG_ EAT_TRANS_SPEED : 39|16@0+ (0.01,0) [0|655.35] ""  OBC

BO_ 2373075402 EAT_158: 8 VCU
 SG_ EAT_CHECKSUM_158 : 59|4@0+ (1,0) [0|15] ""  OBC
 SG_ EAT_ALIVE_COUNTER_158 : 61|2@0+ (1,0) [0|3] ""  OBC
 SG_ EAT_TRANS_SPEED : 39|16@0+ (0.01,0) [0|655.35] ""  OBC

BO_ 2373075403 EAT_158: 8 VCU
 SG_ EAT_CHECKSUM_158 : 59|4@0+ (1,0) [0|15] ""  OBC
 SG_ EAT_ALIVE_COUNTER_158 : 61|2@0+ (1,0) [0|3] ""  OBC
 SG_ EAT_TRANS_SPEED : 39|16@0+ (0.01,0) [0|655.35] ""  OBC

BO_ 2373075404 EAT_158: 8 VCU
 SG_ EAT_CHECKSUM_158 : 59|4@0+ (1,0) [0|15] ""  OBC
 SG_ EAT_ALIVE_COUNTER_158 : 61|2@0+ (1,0) [0|3] ""  OBC
 SG_ EAT_TRANS_SPEED : 39|16@0+ (0.01,0) [0|655.35] ""  OBC

BO_ 2373075405 EAT_158: 8 VCU
 SG_ EAT_CHECKSUM_158 : 59|4@0+ (1,0) [0|15] ""  OBC
 SG_ EAT_ALIVE_COUNTER_158 : 61|2@0+ (1,0) [0|3] ""  OBC
 SG_ EAT_TRANS_SPEED : 39|16@0+ (0.01,0) [0|655.35] ""  OBC

BO_ 2373075406 EAT_158: 8 VCU
 SG_ EAT_CHECKSUM_158 : 59|4@0+ (1,0) [0|15] ""  OBC
 SG_ EAT_ALIVE_COUNTER_158 : 61|2@0+ (1,0) [0|3] ""  OBC
 SG_ EAT_TRANS_SPEED : 39|16@0+ (0.01,0) [0|655.35] ""  OBC

BO_ 2373075407 EAT_158: 8 VCU
 SG_ EAT_CHECKSUM_158 : 59|4@0+ (1,0) [0|15] ""  OBC
 SG_ EAT_ALIVE_COUNTER_158 : 61|2@0+ (1,0) [0|3] ""  OBC
 SG_ EAT_TRANS_SPEED : 39|16@0+ (0.01,0) [0|655.35] ""  OBC

BO_ 2373075408 EAT_158: 8 VCU
 SG_ EAT_CHECKSUM_158 : 59|4@0+ (1,0) [0|15] ""  OBC
 SG_ EAT_ALIVE_COUNTER_158 : 61|2@0+ (1,0) [0|3] ""  OBC
 SG_ EAT_TRANS_SPEED : 39|16@0+ (0.01,0) [0|655.35] ""  OBC

BO_ 2373075409 EAT_158: 8 VCU
 SG_ EAT_CHECKSUM_158 : 59|4@0+ (1,0) [0|15] ""  OBC
 SG_ EAT_ALIVE_COUNTER_158 : 61|2@0+ (1,0) [0|3] ""  OBC
 SG_ EAT_TRANS_SPEED : 39|16@0+ (0.01,0) [0|655.35] ""  OBC

BO_ 2373075410 EAT_158: 8 VCU
 SG_ EAT_CHECKSUM_158 : 59|4@0+ (1,0) [0|15] ""  OBC
 SG_ EAT_ALIVE_COUNTER_158 : 61|2@0+ (1,0) [0|3] ""  OBC
 SG_ EAT_TRANS_SPEED : 39|16@0+ (0.01,0) [0|655.35] ""  OBC

BO_ 2373075411 EAT_158: 8 VCU
 SG_ EAT_CHECKSUM_158 : 59|4@0+ (1,0) [0|15] ""  OBC
 SG_ EAT_ALIVE_COUNTER_158 : 61|2@0+ (1,0) [0|3] ""  OBC
 SG_ EAT_TRANS_SPEED : 39|16@0+ (0.01,0) [0|655.35] ""  OBC

BO_ 2373075412 EAT_158: 8 VCU
 SG_ EAT_CHECKSUM_158 : 59|4@0+ (1,0) [0|15] ""  OBC
 SG_ EAT_ALIVE_COUNTER_158 : 61|2@0+ (1,0) [0|3] ""  OBC
 SG_ EAT_TRANS_SPEED : 39|16@0+ (0.01,0) [0|655.35] ""  OBC

BO_ 2373075413 EAT_158: 8 VCU
 SG_ EAT_CHECKSUM_158 : 59|4@0+ (1,0) [0|15] ""  OBC
 SG_ EAT_ALIVE_COUNTER_158 : 61|2@0+ (1,0) [0|3] ""  OBC
 SG_ EAT_TRANS_SPEED : 39|16@0+ (0.01,0) [0|655.35] ""  OBC

BO_ 2373075414 EAT_158: 8 VCU
 SG_ EAT_CHECKSUM_158 : 59|4@0+ (1,0) [0|15] ""  OBC
 SG_ EAT_ALIVE_COUNTER_158 : 61|2@0+ (1,0) [0|3] ""  OBC
 SG_ EAT_TRANS_SPEED : 39|16@0+ (0.01,0) [0|655.35] ""  OBC

BO_ 2373075415 EAT_158: 8 VCU
 SG_ EAT_CHECKSUM_158 : 59|4@0+ (1,0) [0|15] ""  OBC
 SG_ EAT_ALIVE_COUNTER_158 : 61|2@0+ (1,0) [0|3] ""  OBC
 SG_ EAT_TRANS_SPEED : 39|16@0+ (0.01,0) [0|655.35] ""  OBC

BO_ 2373075416 EAT_158: 8 VCU
 SG_ EAT_CHECKSUM_158 : 59|4@0+ (1,0) [0|15] ""  OBC
 SG_ EAT_ALIVE_COUNTER_158 : 61|2@0+ (1,0) [0|3] ""  OBC
 SG_ EAT_TRANS_SPEED : 39|16@0+ (0.01,0) [0|655.35] ""  OBC

BO_ 2373075417 EAT_158: 8 VCU
 SG_ EAT_CHECKSUM_158 : 59|4@0+ (1,0) [0|15] ""  OBC
 SG_ EAT_ALIVE_COUNTER_158 : 61|2@0+ (1,0) [0|3] ""  OBC
 SG_ EAT_TRANS_SPEED : 39|16@0+ (0.01,0) [0|655.35] ""  OBC

BO_ 2373075418 EAT_158: 8 VCU
 SG_ EAT_CHECKSUM_158 : 59|4@0+ (1,0) [0|15] ""  OBC
 SG_ EAT_ALIVE_COUNTER_158 : 61|2@0+ (1,0) [0|3] ""  OBC
 SG_ EAT_TRANS_SPEED : 39|16@0+ (0.01,0) [0|655.35] ""  OBC

BO_ 2373075419 EAT_158: 8 VCU
 SG_ EAT_CHECKSUM_158 : 59|4@0+ (1,0) [0|15] ""  OBC
 SG_ EAT_ALIVE_COUNTER_158 : 61|2@0+ (1,0) [0|3] ""  OBC
 SG_ EAT_TRANS_SPEED : 39|16@0+ (0.01,0) [0|655.35] ""  OBC

BO_ 2373075420 EAT_158: 8 VCU
 SG_ EAT_CHECKSUM_158 : 59|4@0+ (1,0) [0|15] ""  OBC
 SG_ EAT_ALIVE_COUNTER_158 : 61|2@0+ (1,0) [0|3] ""  OBC
 SG_ EAT_TRANS_SPEED : 39|16@0+ (0.01,0) [0|655.35] ""  OBC

BO_ 2373075421 EAT_158: 8 VCU
 SG_ EAT_CHECKSUM_158 : 59|4@0+ (1,0) [0|15] ""  OBC
 SG_ EAT_ALIVE_COUNTER_158 : 61|2@0+ (1,0) [0|3] ""  OBC
 SG_ EAT_TRANS_SPEED : 39|16@0+ (0.01,0) [0|655.35] ""  OBC

BO_ 2373075422 EAT_158: 8 VCU
 SG_ EAT_CHECKSUM_158 : 59|4@0+ (1,0) [0|15] ""  OBC
 SG_ EAT_ALIVE_COUNTER_158 : 61|2@0+ (1,0) [0|3] ""  OBC
 SG_ EAT_TRANS_SPEED : 39|16@0+ (0.01,0) [0|655.35] ""  OBC

BO_ 2373075423 EAT_158: 8 VCU
 SG_ EAT_CHECKSUM_158 : 59|4@0+ (1,0) [0|15] ""  OBC
 SG_ EAT_ALIVE_COUNTER_158 : 61|2@0+ (1,0) [0|3] ""  OBC
 SG_ EAT_TRANS_SPEED : 39|16@0+ (0.01,0) [0|655.35] ""  OBC

BO_ 2373075424 EAT_158: 8 VCU
 SG_ EAT_CHECKSUM_158 : 59|4@0+ (1,0) [0|15] ""  OBC
 SG_ EAT_ALIVE_COUNTER_158 : 61|2@0+ (1,0) [0|3] ""  OBC
 SG_ EAT_TRANS_SPEED : 39|16@0+ (0.01,0) [0|655.35] ""  OBC

BO_ 2373075425 EAT_158: 8 VCU
 SG_ EAT_CHECKSUM_158 : 59|4@0+ (1,0) [0|15] ""  OBC
 SG_ EAT_ALIVE_COUNTER_158 : 61|2@0+ (1,0) [0|3] ""  OBC
 SG_ EAT_TRANS_SPEED : 39|16@0+ (0.01,0) [0|655.35] ""  OBC

BO_ 2373075426 EAT_158: 8 VCU
 SG_ EAT_CHECKSUM_158 : 59|4@0+ (1,0) [0|15] ""  OBC
 SG_ EAT_ALIVE_COUNTER_158 : 61|2@0+ (1,0) [0|3] ""  OBC
 SG_ EAT_TRANS_SPEED : 39|16@0+ (0.01,0) [0|655.35] ""  OBC

BO_ 2373075427 EAT_158: 8 VCU
 SG_ EAT_CHECKSUM_158 : 59|4@0+ (1,0) [0|15] ""  OBC
 SG_ EAT_ALIVE_COUNTER_158 : 61|2@0+ (1,0) [0|3] ""  OBC
 SG_ EAT_TRANS_SPEED : 39|16@0+ (0.01,0) [0|655.35] ""  OBC

BO_ 2373075428 EAT_158: 8 VCU
 SG_ EAT_CHECKSUM_158 : 59|4@0+ (1,0) [0|15] ""  OBC
 SG_ EAT_ALIVE_COUNTER_158 : 61|2@0+ (1,0) [0|3] ""  OBC
 SG_ EAT_TRANS_SPEED : 39|16@0+ (0.01,0) [0|655.35] ""  OBC

BO_ 2373075429 EAT_158: 8 VCU
 SG_ EAT_CHECKSUM_158 : 59|4@0+ (1,0) [0|15] ""  OBC
 SG_ EAT_ALIVE_COUNTER_158 : 61|2@0+ (1,0) [0|3] ""  OBC
 SG_ EAT_TRANS_SPEED : 39|16@0+ (0.01,0) [0|655.35] ""  OBC

BO_ 2373075430 EAT_158: 8 VCU
 SG_ EAT_CHECKSUM_158 : 59|4@0+ (1,0) [0|15] ""  OBC
 SG_ EAT_ALIVE_COUNTER_158 : 61|2@0+ (1,0) [0|3] ""  OBC
 SG_ EAT_TRANS_SPEED : 39|16@0+ (0.01,0) [0|655.35] ""  OBC

BO_ 2373075431 EAT_158: 8 VCU
 SG_ EAT_CHECKSUM_158 : 59|4@0+ (1,0) [0|15] ""  OBC
 SG_ EAT_ALIVE_COUNTER_158 : 61|2@0+ (1,0) [0|3] ""  OBC
 SG_ EAT_TRANS_SPEED : 39|16@0+ (0.01,0) [0|655.35] ""  OBC

BO_ 2373075432 EAT_158: 8 VCU
 SG_ EAT_CHECKSUM_158 : 59|4@0+ (1,0) [0|15] ""  OBC
 SG_ EAT_ALIVE_COUNTER_158 : 61|2@0+ (1,0) [0|3] ""  OBC
 SG_ EAT_TRANS_SPEED : 39|16@0+ (0.01,0) [0|655.35] ""  OBC

BO_ 2373075433 EAT_158: 8 VCU
 SG_ EAT_CHECKSUM_158 : 59|4@0+ (1,0) [0|15] ""  OBC
 SG_ EAT_ALIVE_COUNTER_158 : 61|2@0+ (1,0) [0|3] ""  OBC
 SG_ EAT_TRANS_SPEED : 39|16@0+ (0.01,0) [0|655.35] ""  OBC

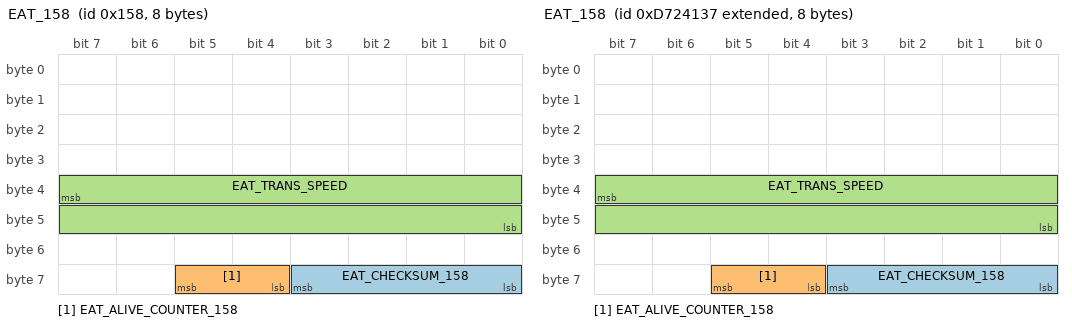
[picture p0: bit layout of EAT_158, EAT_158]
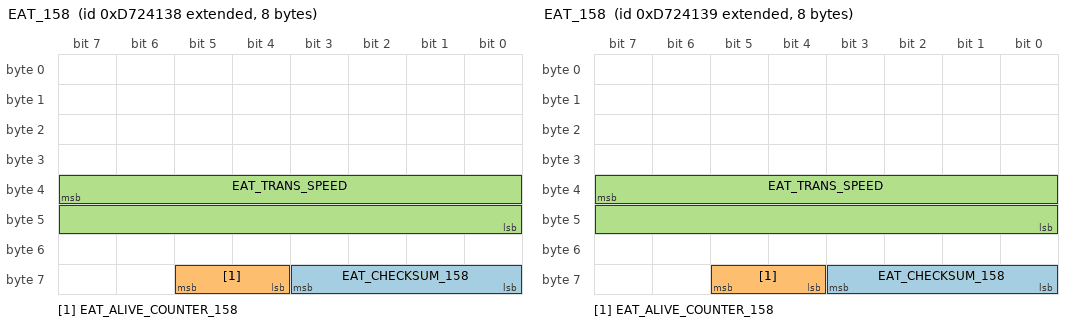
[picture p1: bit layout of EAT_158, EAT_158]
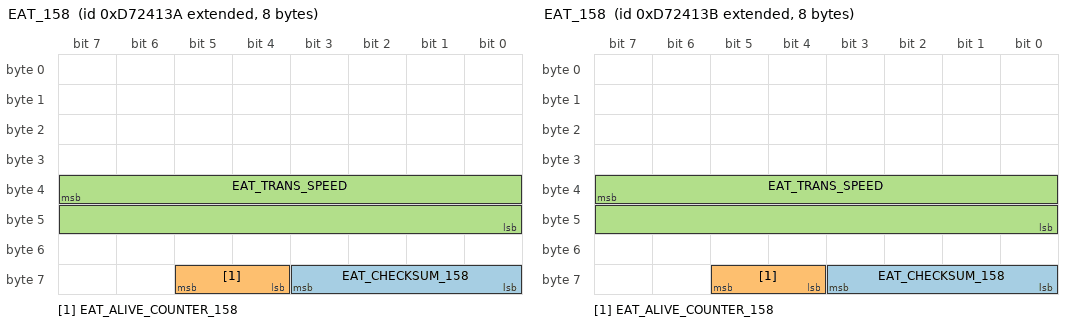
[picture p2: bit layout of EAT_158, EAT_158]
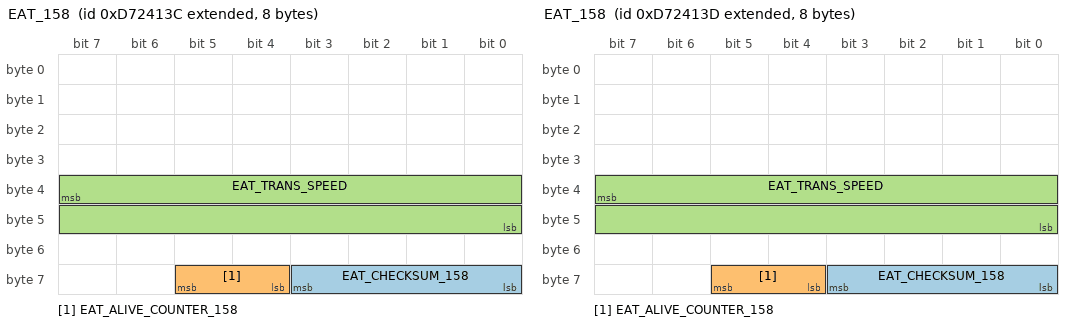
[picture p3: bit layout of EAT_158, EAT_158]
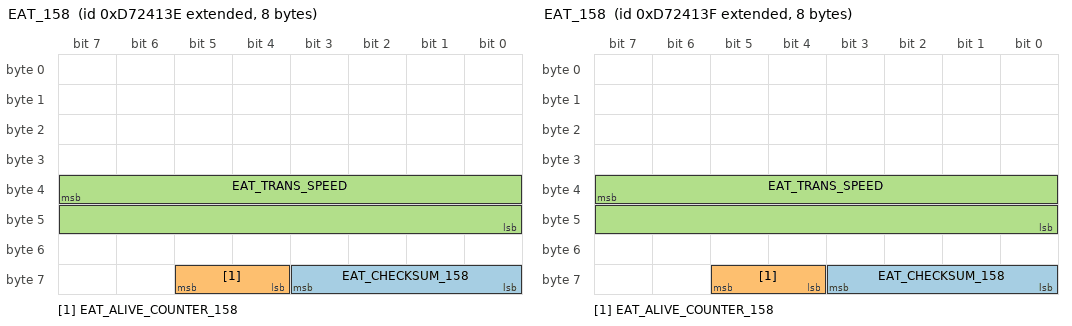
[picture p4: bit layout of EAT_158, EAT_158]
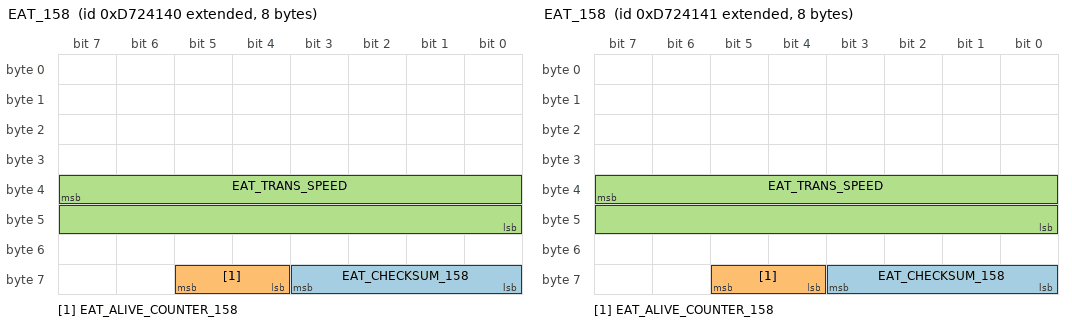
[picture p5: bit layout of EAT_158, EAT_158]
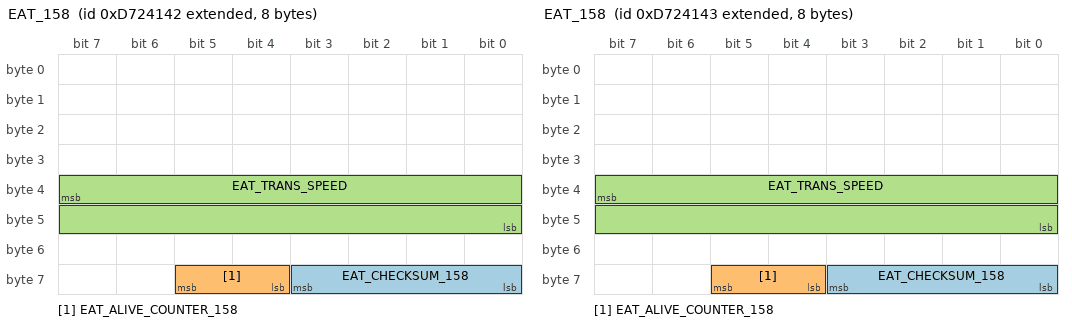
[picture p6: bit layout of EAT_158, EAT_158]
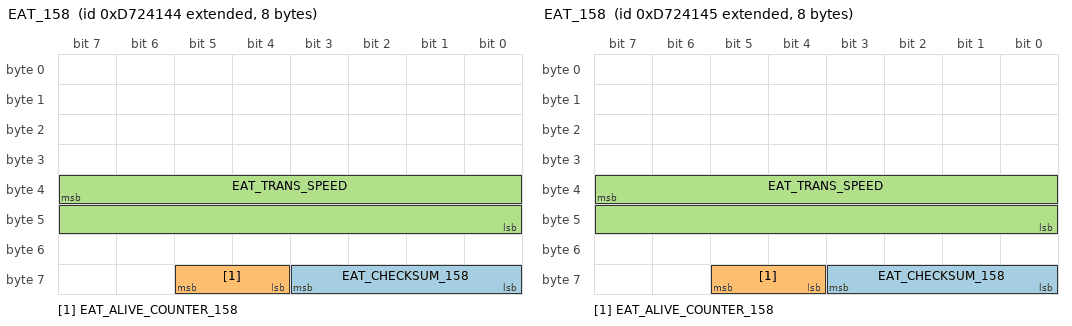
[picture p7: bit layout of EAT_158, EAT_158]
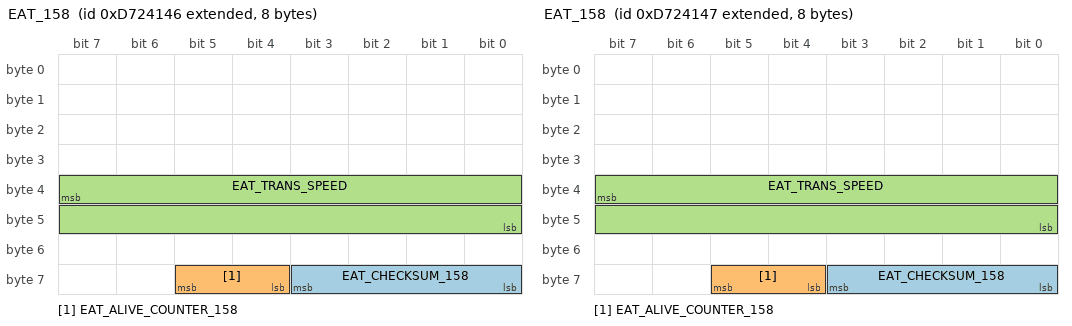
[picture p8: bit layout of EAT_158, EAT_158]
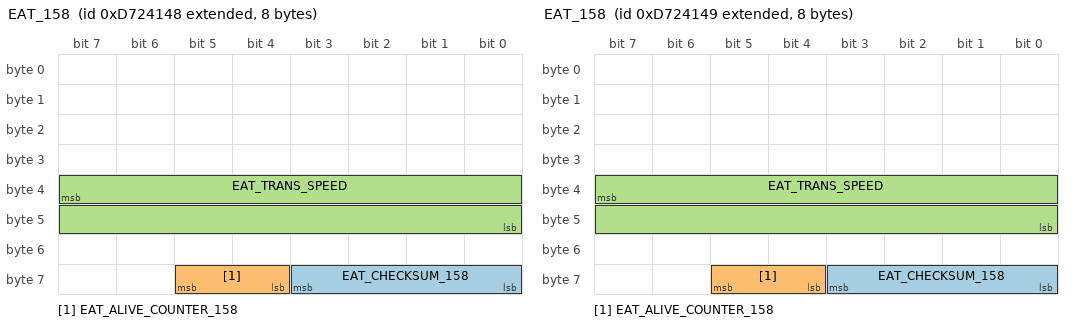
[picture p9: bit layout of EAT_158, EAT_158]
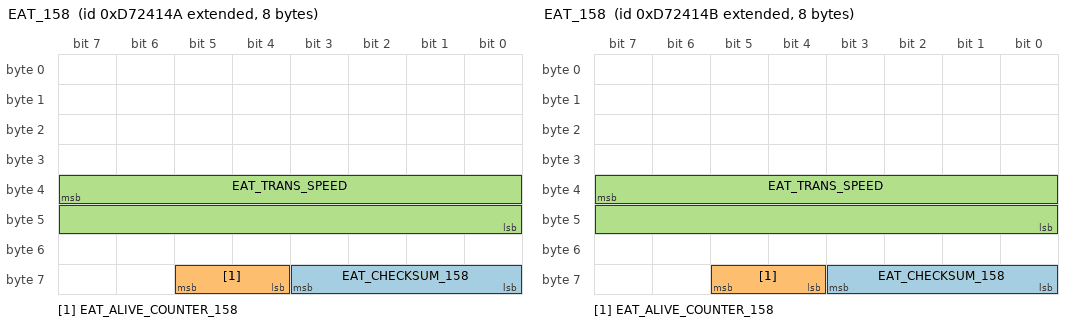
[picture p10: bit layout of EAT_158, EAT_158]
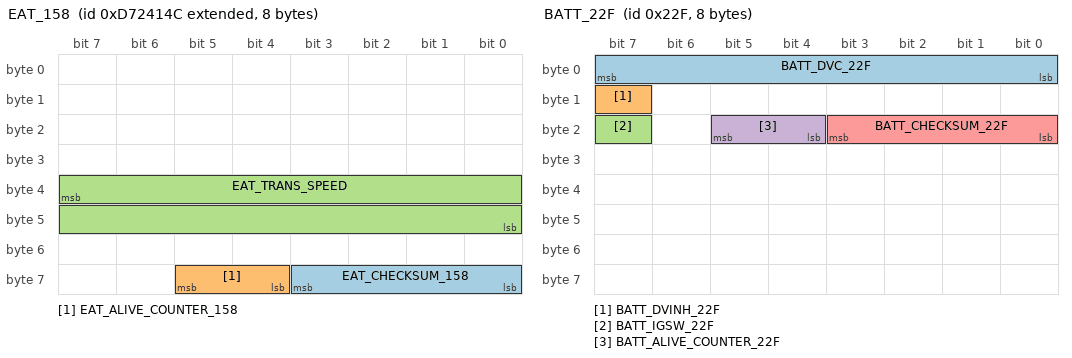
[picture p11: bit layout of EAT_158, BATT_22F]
BO_ 2373075434 EAT_158: 8 VCU
 SG_ EAT_CHECKSUM_158 : 59|4@0+ (1,0) [0|15] ""  OBC
 SG_ EAT_ALIVE_COUNTER_158 : 61|2@0+ (1,0) [0|3] ""  OBC
 SG_ EAT_TRANS_SPEED : 39|16@0+ (0.01,0) [0|655.35] ""  OBC

BO_ 2483042311 VCU_14003807: 8 VCU
 SG_ VCU_NM_PNI : 14|1@0+ (1,0) [0|0] "" Vector__XXX
 SG_ CHG_UNIT_Start_Request : 53|1@0+ (1,0) [0|0] ""  OBC

BO_ 2483042526 OBC_140038DE: 8 OBC
 SG_ CHG_NM_PNI : 14|1@0+ (1,0) [0|0] ""  VCU
 SG_ PT_Domain_Start_Request : 21|1@0+ (1,0) [0|0] ""  VCU

BO_ 559 BATT_22F: 8 VCU
 SG_ BATT_DVC_22F : 7|8@0+ (0.1,0) [0|25.5] "V"  DCDC
 SG_ BATT_DVINH_22F : 15|1@0+ (1,0) [0|1] ""  DCDC
 SG_ BATT_IGSW_22F : 23|1@0+ (1,0) [0|1] ""  DCDC
 SG_ BATT_ALIVE_COUNTER_22F : 21|2@0+ (1,0) [0|3] ""  DCDC
 SG_ BATT_CHECKSUM_22F : 19|4@0+ (1,0) [0|15] ""  DCDC

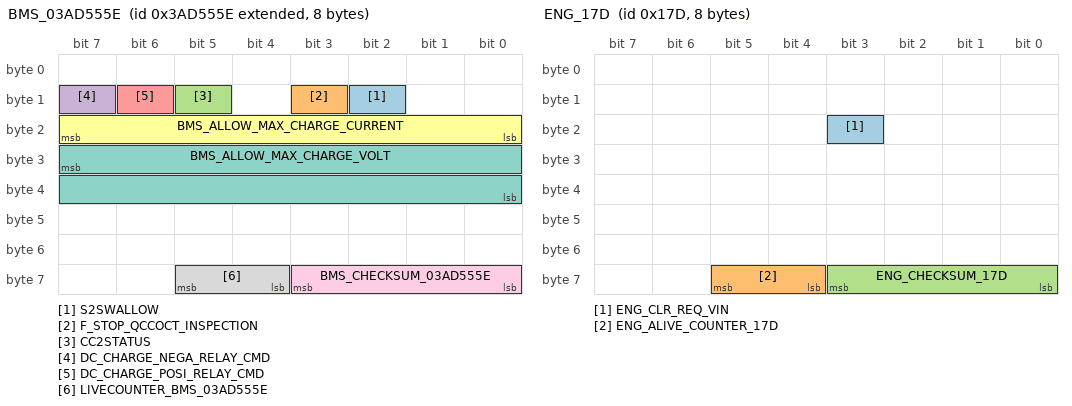
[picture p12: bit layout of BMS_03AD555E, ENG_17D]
BO_ 2209174878 BMS_03AD555E: 8 BMS
 SG_ S2SWALLOW : 10|1@0+ (1,0) [0|1] ""  OBC
 SG_ F_STOP_QCCOCT_INSPECTION : 11|1@0+ (1,0) [0|1] ""  OBC
 SG_ CC2STATUS : 13|1@0+ (1,0) [0|1] ""  OBC
 SG_ DC_CHARGE_NEGA_RELAY_CMD : 15|1@0+ (1,0) [0|1] ""  OBC
 SG_ DC_CHARGE_POSI_RELAY_CMD : 14|1@0+ (1,0) [0|1] ""  OBC
 SG_ BMS_ALLOW_MAX_CHARGE_CURRENT : 23|8@0+ (0.1,0) [0|25.5] "A"  OBC
 SG_ BMS_ALLOW_MAX_CHARGE_VOLT : 31|16@0+ (0.01,0) [0|655.349976] "V"  OBC
 SG_ LIVECOUNTER_BMS_03AD555E : 61|2@0+ (1,0) [0|3] ""  OBC
 SG_ BMS_CHECKSUM_03AD555E : 59|4@0+ (1,0) [0|15] ""  OBC

BO_ 381 ENG_17D: 8 VCU
 SG_ ENG_CLR_REQ_VIN : 19|1@0+ (1,0) [0|1] ""  OBC,BMS
 SG_ ENG_ALIVE_COUNTER_17D : 61|2@0+ (1,0) [0|3] ""  OBC,BMS
 SG_ ENG_CHECKSUM_17D : 59|4@0+ (1,0) [0|15] ""  OBC,BMS

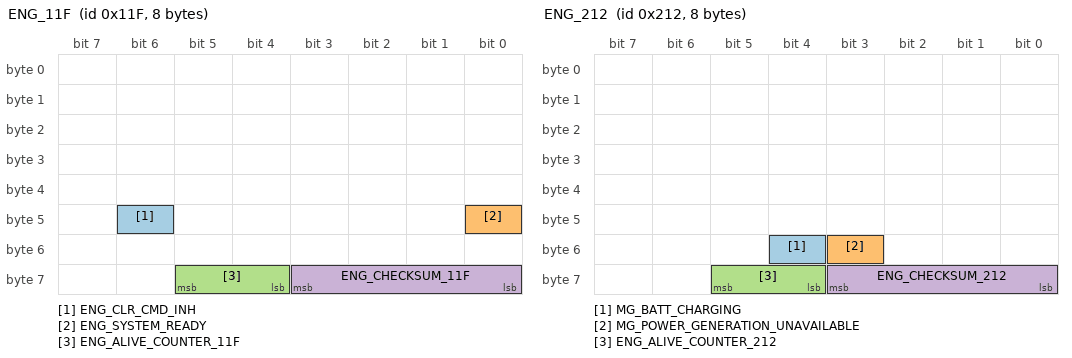
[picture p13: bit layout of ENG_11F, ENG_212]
BO_ 287 ENG_11F: 8 VCU
 SG_ ENG_CLR_CMD_INH : 46|1@0+ (1,0) [0|1] ""  OBC,BMS
 SG_ ENG_SYSTEM_READY : 40|1@0+ (1,0) [0|1] ""  OBC,BMS
 SG_ ENG_ALIVE_COUNTER_11F : 61|2@0+ (1,0) [0|3] ""  OBC,BMS
 SG_ ENG_CHECKSUM_11F : 59|4@0+ (1,0) [0|15] ""  OBC,BMS

BO_ 530 ENG_212: 8 VCU
 SG_ MG_BATT_CHARGING : 52|1@0+ (1,0) [0|1] ""  OBC,BMS
 SG_ MG_POWER_GENERATION_UNAVAILABLE : 51|1@0+ (1,0) [0|1] ""  OBC,BMS
 SG_ ENG_ALIVE_COUNTER_212 : 61|2@0+ (1,0) [0|3] "-"  OBC,BMS
 SG_ ENG_CHECKSUM_212 : 59|4@0+ (1,0) [0|15] "-"  OBC,BMS

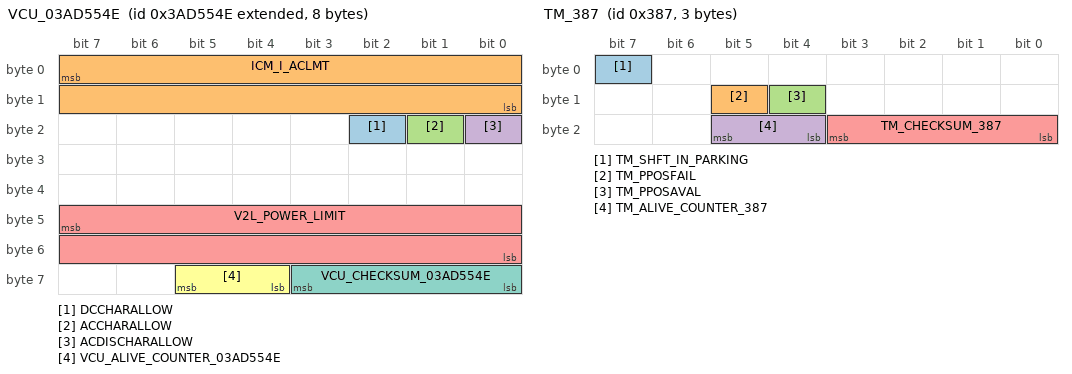
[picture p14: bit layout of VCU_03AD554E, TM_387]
BO_ 2209174862 VCU_03AD554E: 8 VCU
 SG_ DCCHARALLOW : 18|1@0+ (1,0) [0|1] ""  OBC
 SG_ ICM_I_ACLMT : 7|16@0+ (0.1,0) [0|6553.5] "A"  OBC
 SG_ ACCHARALLOW : 17|1@0+ (1,0) [0|1] ""  OBC
 SG_ ACDISCHARALLOW : 16|1@0+ (1,0) [0|1] ""  OBC
 SG_ V2L_POWER_LIMIT : 47|16@0+ (10,-327680) [-327680|327670] "W"  OBC
 SG_ VCU_ALIVE_COUNTER_03AD554E : 61|2@0+ (1,0) [0|3] ""  OBC
 SG_ VCU_CHECKSUM_03AD554E : 59|4@0+ (1,0) [0|15] ""  OBC

BO_ 903 TM_387: 3 VCU
 SG_ TM_SHFT_IN_PARKING : 7|1@0+ (1,0) [0|1] ""  OBC,BMS
 SG_ TM_PPOSFAIL : 13|1@0+ (1,0) [0|1] ""  OBC,BMS
 SG_ TM_PPOSAVAL : 12|1@0+ (1,0) [0|1] ""  OBC,BMS
 SG_ TM_ALIVE_COUNTER_387 : 21|2@0+ (1,0) [0|3] ""  OBC,BMS
 SG_ TM_CHECKSUM_387 : 19|4@0+ (1,0) [0|15] ""  OBC,BMS

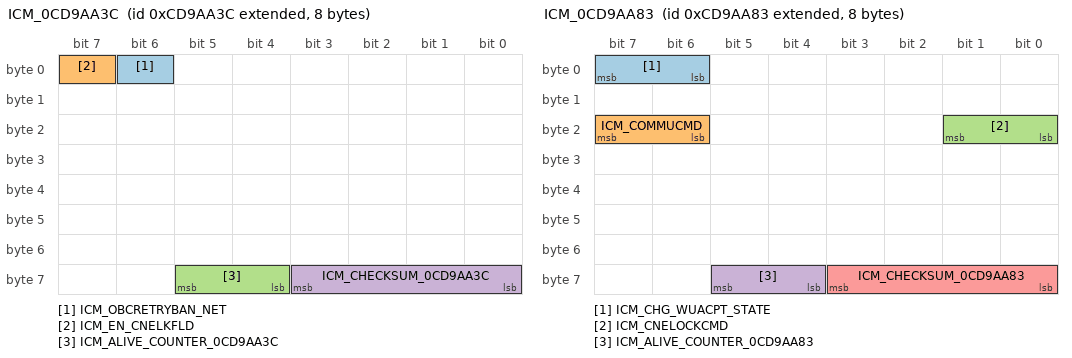
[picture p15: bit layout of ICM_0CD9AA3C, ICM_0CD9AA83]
BO_ 2363075132 ICM_0CD9AA3C: 8 VCU
 SG_ ICM_OBCRETRYBAN_NET : 6|1@0+ (1,0) [0|0] "" Vector__XXX
 SG_ ICM_EN_CNELKFLD : 7|1@0+ (1,0) [0|1] ""  OBC
 SG_ ICM_ALIVE_COUNTER_0CD9AA3C : 61|2@0+ (1,0) [0|3] ""  OBC
 SG_ ICM_CHECKSUM_0CD9AA3C : 59|4@0+ (1,0) [0|15] ""  OBC

BO_ 2363075203 ICM_0CD9AA83: 8 VCU
 SG_ ICM_CHG_WUACPT_STATE : 7|2@0+ (1,0) [0|3] ""  OBC
 SG_ ICM_COMMUCMD : 23|2@0+ (1,0) [0|3] ""  OBC
 SG_ ICM_CNELOCKCMD : 17|2@0+ (1,0) [0|3] ""  OBC
 SG_ ICM_ALIVE_COUNTER_0CD9AA83 : 61|2@0+ (1,0) [0|3] ""  OBC
 SG_ ICM_CHECKSUM_0CD9AA83 : 59|4@0+ (1,0) [0|15] ""  OBC

BO_ 558 DDC12V_22E: 8 DCDC
 SG_ DDC12V_TDV : 7|8@0+ (1,-50) [-50|205] "℃"  VCU
 SG_ DDC12V_IIN : 15|8@0+ (0.1,0) [0|25.5] "A"  VCU
 SG_ DDC12V_IOUT : 23|8@0+ (1,0) [0|255] "A"  BMS,VCU
 SG_ DDC12V_CHG_LAMP : 30|1@0+ (1,0) [0|1] ""  VCU
 SG_ DDC12V_VO_LV : 29|1@0+ (1,0) [0|1] ""  VCU
 SG_ DDC12V_DV_ERR : 28|1@0+ (1,0) [0|1] ""  VCU
 SG_ DDC12V_OT_1 : 27|1@0+ (1,0) [0|1] ""  VCU
 SG_ DDC12V_OC : 26|1@0+ (1,0) [0|1] ""  VCU
 SG_ DDC12V_TS_ERR : 25|1@0+ (1,0) [0|1] ""  VCU
 SG_ DDC12V_RX_ERR : 24|1@0+ (1,0) [0|1] ""  VCU
 SG_ DDC12V_CAN_NON : 39|1@0+ (1,0) [0|1] ""  VCU
 SG_ DDC12V_DV_INH : 38|1@0+ (1,0) [0|1] ""  VCU
 SG_ DDC12V_IG_LV : 37|1@0+ (1,0) [0|1] ""  VCU
 SG_ DDC12V_IG_UV : 36|1@0+ (1,0) [0|1] ""  VCU
 SG_ DDC12V_OT_2 : 35|1@0+ (1,0) [0|1] ""  VCU
 SG_ DDC12V_VO_OV : 34|1@0+ (1,0) [0|1] ""  VCU
 SG_ DDC12V_VI_OV : 33|1@0+ (1,0) [0|1] ""  VCU
 SG_ DDC12V_VI_LV : 32|1@0+ (1,0) [0|1] ""  VCU
 SG_ DDC12V_CAN_ERR : 47|8@0+ (1,0) [0|255] ""  VCU
 SG_ DDC12V_DVC_OUT : 55|8@0+ (0.1,0) [0|25.5] "V"  VCU
 SG_ DDC12V_ALIVE_COUNTER_22E : 61|2@0+ (1,0) [0|3] ""  BMS,VCU
 SG_ DDC12V_CHECKSUM_22E : 59|4@0+ (1,0) [0|15] ""  BMS,VCU

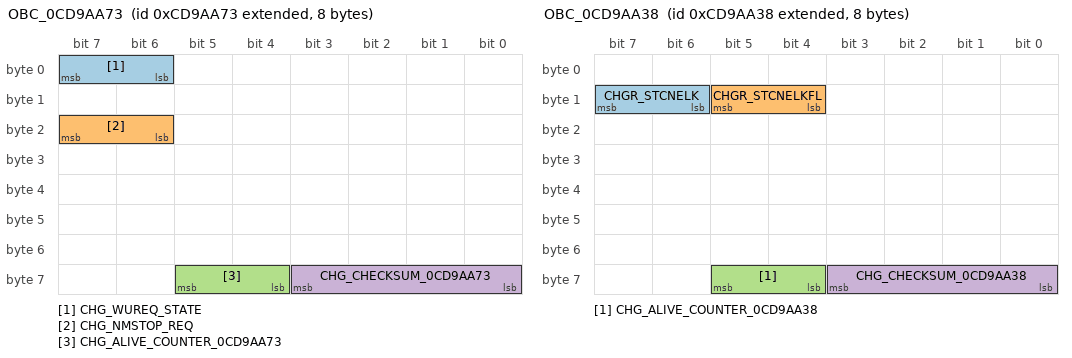
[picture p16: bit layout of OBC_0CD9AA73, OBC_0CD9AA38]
BO_ 2363075187 OBC_0CD9AA73: 8 OBC
 SG_ CHG_WUREQ_STATE : 7|2@0+ (1,0) [0|0] ""  VCU
 SG_ CHG_NMSTOP_REQ : 23|2@0+ (1,0) [0|0] ""  VCU
 SG_ CHG_ALIVE_COUNTER_0CD9AA73 : 61|2@0+ (1,0) [0|0] ""  VCU
 SG_ CHG_CHECKSUM_0CD9AA73 : 59|4@0+ (1,0) [0|0] ""  VCU

BO_ 2363075128 OBC_0CD9AA38: 8 OBC
 SG_ CHGR_STCNELK : 15|2@0+ (1,0) [0|3] ""  VCU,BMS
 SG_ CHGR_STCNELKFL : 13|2@0+ (1,0) [0|3] ""  VCU,BMS
 SG_ CHG_ALIVE_COUNTER_0CD9AA38 : 61|2@0+ (1,0) [0|0] ""  VCU,BMS
 SG_ CHG_CHECKSUM_0CD9AA38 : 59|4@0+ (1,0) [0|0] ""  VCU,BMS

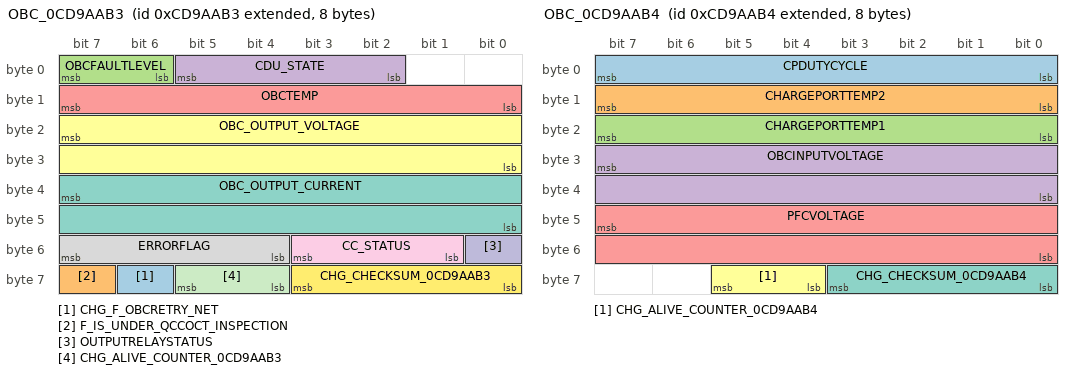
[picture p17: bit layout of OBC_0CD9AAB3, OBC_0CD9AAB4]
BO_ 2363075251 OBC_0CD9AAB3: 8 OBC
 SG_ CHG_F_OBCRETRY_NET : 62|1@0+ (1,0) [0|1] "" Vector__XXX
 SG_ F_IS_UNDER_QCCOCT_INSPECTION : 63|1@0+ (1,0) [0|1] "" Vector__XXX
 SG_ OBCFAULTLEVEL : 7|2@0+ (1,0) [0|0] ""  VCU,BMS
 SG_ CDU_STATE : 5|4@0+ (1,0) [0|0] ""  VCU,BMS
 SG_ OBCTEMP : 15|8@0+ (1,-40) [0|0] "℃"  VCU,BMS
 SG_ OBC_OUTPUT_VOLTAGE : 23|16@0+ (0.1,0) [0|0] "V"  VCU,BMS
 SG_ OBC_OUTPUT_CURRENT : 39|16@0+ (0.1,-40) [0|0] "A"  VCU,BMS
 SG_ ERRORFLAG : 55|4@0+ (1,0) [0|0] ""  VCU,BMS
 SG_ CC_STATUS : 51|3@0+ (1,0) [0|0] ""  VCU,BMS
 SG_ OUTPUTRELAYSTATUS : 48|1@0+ (1,0) [0|0] ""  VCU,BMS
 SG_ CHG_ALIVE_COUNTER_0CD9AAB3 : 61|2@0+ (1,0) [0|0] ""  VCU,BMS
 SG_ CHG_CHECKSUM_0CD9AAB3 : 59|4@0+ (1,0) [0|0] ""  VCU,BMS

BO_ 2363075252 OBC_0CD9AAB4: 8 OBC
 SG_ CPDUTYCYCLE : 7|8@0+ (1,0) [0|0] "%"  VCU,BMS
 SG_ CHARGEPORTTEMP2 : 15|8@0+ (1,-40) [0|0] "℃"  VCU,BMS
 SG_ CHARGEPORTTEMP1 : 23|8@0+ (1,-40) [0|0] "℃"  VCU,BMS
 SG_ OBCINPUTVOLTAGE : 31|16@0+ (0.1,0) [0|0] "V"  VCU,BMS
 SG_ PFCVOLTAGE : 47|16@0+ (0.1,0) [0|0] "V"  VCU,BMS
 SG_ CHG_ALIVE_COUNTER_0CD9AAB4 : 61|2@0+ (1,0) [0|0] ""  VCU,BMS
 SG_ CHG_CHECKSUM_0CD9AAB4 : 59|4@0+ (1,0) [0|0] ""  VCU,BMS

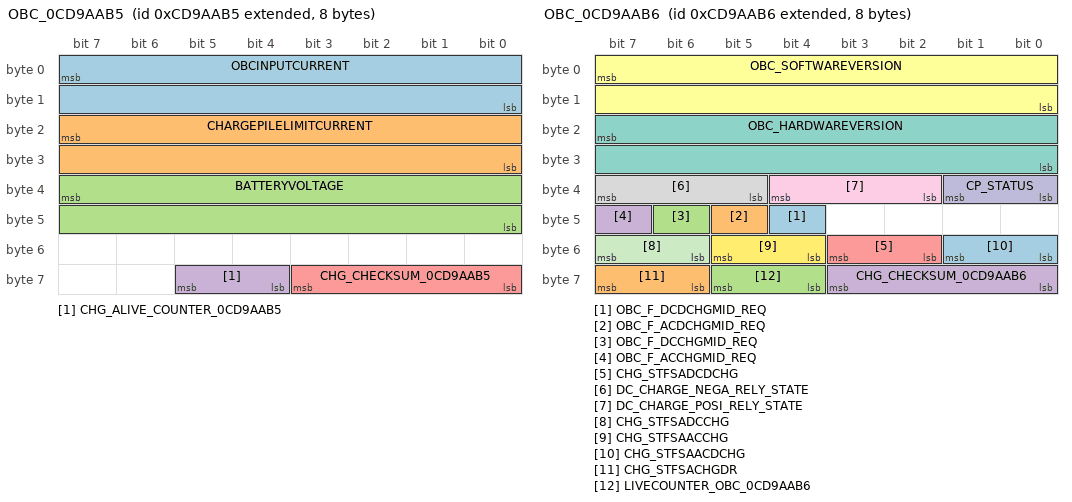
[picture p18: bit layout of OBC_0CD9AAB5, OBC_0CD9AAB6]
BO_ 2363075253 OBC_0CD9AAB5: 8 OBC
 SG_ OBCINPUTCURRENT : 7|16@0+ (0.1,-40) [0|0] "A"  VCU,BMS
 SG_ CHARGEPILELIMITCURRENT : 23|16@0+ (0.1,-40) [0|0] "A"  VCU,BMS
 SG_ BATTERYVOLTAGE : 39|16@0+ (0.1,0) [0|0] "V"  VCU,BMS
 SG_ CHG_ALIVE_COUNTER_0CD9AAB5 : 61|2@0+ (1,0) [0|0] ""  VCU,BMS
 SG_ CHG_CHECKSUM_0CD9AAB5 : 59|4@0+ (1,0) [0|0] ""  VCU,BMS

BO_ 2363075254 OBC_0CD9AAB6: 8 OBC
 SG_ OBC_F_DCDCHGMID_REQ : 44|1@0+ (1,0) [0|1] "" Vector__XXX
 SG_ OBC_F_ACDCHGMID_REQ : 45|1@0+ (1,0) [0|1] "" Vector__XXX
 SG_ OBC_F_DCCHGMID_REQ : 46|1@0+ (1,0) [0|1] "" Vector__XXX
 SG_ OBC_F_ACCHGMID_REQ : 47|1@0+ (1,0) [0|1] "" Vector__XXX
 SG_ CHG_STFSADCDCHG : 51|2@0+ (1,0) [0|3] "" Vector__XXX
 SG_ OBC_SOFTWAREVERSION : 7|16@0+ (1,0) [0|0] "" Vector__XXX
 SG_ OBC_HARDWAREVERSION : 23|16@0+ (1,0) [0|0] "" Vector__XXX
 SG_ DC_CHARGE_NEGA_RELY_STATE : 39|3@0+ (1,0) [0|0] ""  BMS
 SG_ DC_CHARGE_POSI_RELY_STATE : 36|3@0+ (1,0) [0|0] ""  BMS
 SG_ CP_STATUS : 33|2@0+ (1,0) [0|0] ""  VCU
 SG_ CHG_STFSADCCHG : 55|2@0+ (1,0) [0|0] ""  VCU
 SG_ CHG_STFSAACCHG : 53|2@0+ (1,0) [0|0] ""  VCU
 SG_ CHG_STFSAACDCHG : 49|2@0+ (1,0) [0|0] ""  VCU
 SG_ CHG_STFSACHGDR : 63|2@0+ (1,0) [0|0] ""  VCU
 SG_ LIVECOUNTER_OBC_0CD9AAB6 : 61|2@0+ (1,0) [0|0] ""  BMS
 SG_ CHG_CHECKSUM_0CD9AAB6 : 59|4@0+ (1,0) [0|0] ""  BMS

BO_ 2363075255 OBC_0CD9AAB7: 8 OBC
 SG_ OBC_12VSTATUS : 47|1@0+ (1,0) [0|0] "" Vector__XXX
 SG_ CC_RESISTANCE : 7|16@0+ (1,0) [0|65535] "Ω" Vector__XXX
 SG_ DC_CHARGE_IP_VOLT : 23|16@0+ (1,0) [0|65535] "V" Vector__XXX
 SG_ CHGR_LICMDSTP : 46|1@0+ (1,0) [0|0] ""  VCU
 SG_ S2STATUS : 45|1@0+ (1,0) [0|0] "" Vector__XXX
 SG_ CANIP_OBC_INTER_OVERTEMP : 44|1@0+ (1,0) [0|0] "" Vector__XXX
 SG_ CANIP_BOOL_OBC_IP_UNDERVOLT : 43|1@0+ (1,0) [0|0] "" Vector__XXX
 SG_ CANIP_BOOL_OBC_IP_OVERVOLT : 42|1@0+ (1,0) [0|0] "" Vector__XXX
 SG_ CANIP_BOOL_OBC_PFC_OVERVOLT : 41|1@0+ (1,0) [0|0] "" Vector__XXX
 SG_ CANIP_BOOL_CHARSEATTEMPNOTFIND : 40|1@0+ (1,0) [0|0] "" Vector__XXX
 SG_ OBC_POWERSYS_REQ : 55|1@0+ (1,0) [0|0] "" Vector__XXX
 SG_ OBC_12V_WARN_MID_REQ : 54|1@0+ (1,0) [0|0] "" Vector__XXX
 SG_ CANIP_AC_CHARGING_PILE_ERROR : 53|1@0+ (1,0) [0|0] ""  BMS,VCU
 SG_ CANIP_BOOL_OBC_OP_OVERCURRENT : 52|1@0+ (1,0) [0|0] ""  BMS,VCU
 SG_ CANIP_BOOL_OBC_OP_UNDERVOLT : 51|1@0+ (1,0) [0|0] "" Vector__XXX
 SG_ CANIP_BOOL_OBC_OP_OVERVOLT : 50|1@0+ (1,0) [0|0] "" Vector__XXX
 SG_ CANIP_BOOL_CHECKSUMERROR : 49|1@0+ (1,0) [0|0] "" Vector__XXX
 SG_ CANIP_BOOL_ACCHAR_SEAT_OVERTEMP : 48|1@0+ (1,0) [0|0] "" Vector__XXX
 SG_ CHG_ALIVE_COUNTER_0CD9AAB7 : 61|2@0+ (1,0) [0|0] ""  VCU
 SG_ CHG_CHECKSUM_0CD9AAB7 : 59|4@0+ (1,0) [0|0] ""  VCU

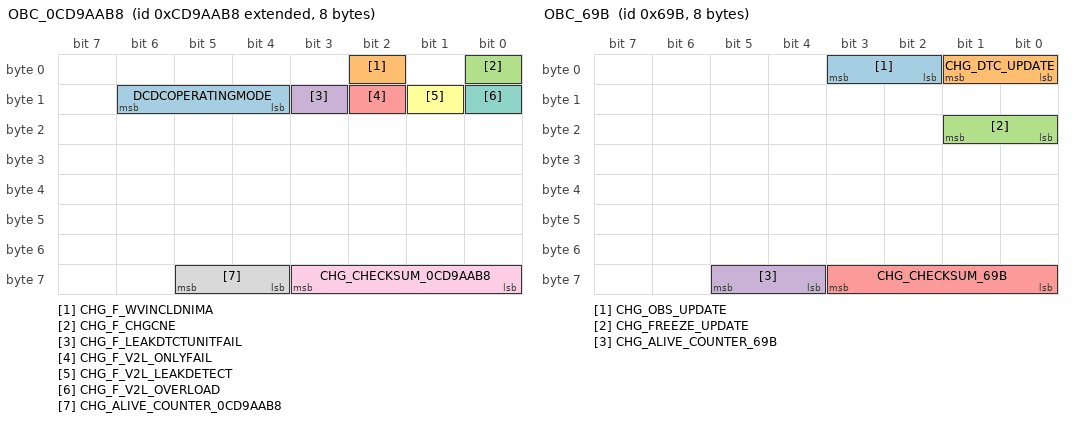
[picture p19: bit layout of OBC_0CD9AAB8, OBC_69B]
BO_ 2363075256 OBC_0CD9AAB8: 8 OBC
 SG_ DCDCOPERATINGMODE : 14|3@0+ (1,0) [0|7] "" Vector__XXX
 SG_ CHG_F_WVINCLDNIMA : 2|1@0+ (1,0) [0|0] ""  VCU
 SG_ CHG_F_CHGCNE : 0|1@0+ (1,0) [0|0] ""  VCU
 SG_ CHG_F_LEAKDTCTUNITFAIL : 11|1@0+ (1,0) [0|0] ""  VCU
 SG_ CHG_F_V2L_ONLYFAIL : 10|1@0+ (1,0) [0|0] ""  VCU
 SG_ CHG_F_V2L_LEAKDETECT : 9|1@0+ (1,0) [0|0] ""  VCU
 SG_ CHG_F_V2L_OVERLOAD : 8|1@0+ (1,0) [0|0] ""  VCU
 SG_ CHG_ALIVE_COUNTER_0CD9AAB8 : 61|2@0+ (1,0) [0|0] ""  VCU
 SG_ CHG_CHECKSUM_0CD9AAB8 : 59|4@0+ (1,0) [0|0] ""  VCU

BO_ 1691 OBC_69B: 8 OBC
 SG_ CHG_OBS_UPDATE : 3|2@0+ (1,0) [0|0] ""  VCU
 SG_ CHG_DTC_UPDATE : 1|2@0+ (1,0) [0|0] ""  VCU
 SG_ CHG_FREEZE_UPDATE : 17|2@0+ (1,0) [0|0] ""  VCU
 SG_ CHG_ALIVE_COUNTER_69B : 61|2@0+ (1,0) [0|0] ""  VCU
 SG_ CHG_CHECKSUM_69B : 59|4@0+ (1,0) [0|0] ""  VCU

CM_ SG_ 559 BATT_DVC_22F "输出指示电压";
CM_ SG_ 559 BATT_DVINH_22F "操作禁止信号";
CM_ SG_ 559 BATT_IGSW_22F "IG开启信号";
CM_ SG_ 2209174878 S2SWALLOW "BMS的S2SW许可
0:S2SW-无ON许可




1:S2SW-有ON许可";
CM_ SG_ 2209174878 F_STOP_QCCOCT_INSPECTION "0：无停止要求




1：有停止请求";
CM_ SG_ 2209174878 CC2STATUS "0：无嵌合




1：有嵌合";
CM_ SG_ 2209174878 BMS_ALLOW_MAX_CHARGE_CURRENT "BMS允许最大充电电流";
CM_ SG_ 2209174878 BMS_ALLOW_MAX_CHARGE_VOLT "BMS允许最大充电电压";
CM_ SG_ 381 ENG_CLR_REQ_VIN "VIN清除请求";
CM_ SG_ 287 ENG_SYSTEM_READY "系统准备就绪";
CM_ SG_ 530 MG_BATT_CHARGING "高压电池充电状态
1: Charging
0: Not charging";
CM_ SG_ 530 MG_POWER_GENERATION_UNAVAILABLE "无法放电
1: Power generation unavailable
0: Power generation available";
CM_ SG_ 2209174862 DCCHARALLOW "快充允许
0:无效
1:有效";
CM_ SG_ 2209174862 ICM_I_ACLMT "充电交流侧电流限制设定值";
CM_ SG_ 2209174862 ACCHARALLOW "充电允许";
CM_ SG_ 2209174862 ACDISCHARALLOW "放电允许";
CM_ SG_ 2209174862 V2L_POWER_LIMIT "放电功率限制";
CM_ SG_ 903 TM_SHFT_IN_PARKING "停车位置信息 PARKING";
CM_ SG_ 2363075132 ICM_EN_CNELKFLD "电锁故障检知允许
0: Undecided
1: Allow detection";
CM_ SG_ 2363075203 ICM_CHG_WUACPT_STATE "启动因素
0: No request
1: activation request
2: deactivation request";
CM_ SG_ 2363075203 ICM_COMMUCMD "通讯指示
0: No request
1: activation request
2: deactivation request";
CM_ SG_ 2363075203 ICM_CNELOCKCMD "电锁命令
0: No request
1: Lock request
2: Unlock request";
CM_ SG_ 558 DDC12V_TDV "检测温度";
CM_ SG_ 558 DDC12V_IIN "输入电流";
CM_ SG_ 558 DDC12V_IOUT "输出电流";
CM_ SG_ 558 DDC12V_CHG_LAMP "警示灯照明要求";
CM_ SG_ 558 DDC12V_VO_LV "输出低电压警告";
CM_ SG_ 558 DDC12V_DV_ERR "内部故障";
CM_ SG_ 558 DDC12V_OT_1 "省电";
CM_ SG_ 558 DDC12V_OC "输出过流保护";
CM_ SG_ 558 DDC12V_TS_ERR "温度传感器错误";
CM_ SG_ 558 DDC12V_RX_ERR "CAN接收错误";
CM_ SG_ 558 DDC12V_CAN_NON "启动时无通讯";
CM_ SG_ 558 DDC12V_DV_INH "内部INH信息";
CM_ SG_ 558 DDC12V_IG_LV "IG低压警告2";
CM_ SG_ 558 DDC12V_IG_UV "IG低压警告1";
CM_ SG_ 558 DDC12V_OT_2 "过热停止";
CM_ SG_ 558 DDC12V_VO_OV "输出过压保护";
CM_ SG_ 558 DDC12V_VI_OV "输入过压保护";
CM_ SG_ 558 DDC12V_VI_LV "输入低电压警告";
CM_ SG_ 558 DDC12V_CAN_ERR "接收错误计数器";
CM_ SG_ 558 DDC12V_DVC_OUT "输出端子检测电压";
CM_ SG_ 2363075187 CHG_WUREQ_STATE "OBC启动原因
0: No request
1: activation request
2: deactivation request";
CM_ SG_ 2363075187 CHG_NMSTOP_REQ "网络管理停止请求
0: before judgement
1: working
2: SLEEP ready";
CM_ SG_ 2363075128 CHGR_STCNELK "电锁状态
0: Undecided
1: Unlocked
2: Locked";
CM_ SG_ 2363075128 CHGR_STCNELKFL "电锁故障
0: Undecided
1: Lock mistake
2: Lock impossible failure
3: Unlock impossible failure";
CM_ SG_ 2363075251 CHG_F_OBCRETRY_NET "因充电设备异常重启中
0: Not retrying
1: Now retrying";
CM_ SG_ 2363075251 F_IS_UNDER_QCCOCT_INSPECTION "快充继电器粘连检测中
0: 検知停止中
1: 検知実行中";
CM_ SG_ 2363075251 OBCFAULTLEVEL "OBC故障等级
0: No fault
1: Level-1 fault
2: Level-2 fault";
CM_ SG_ 2363075251 CDU_STATE "系统状态";
CM_ SG_ 2363075251 OBCTEMP "OBC温度";
CM_ SG_ 2363075251 OBC_OUTPUT_VOLTAGE "OBC高压侧电压";
CM_ SG_ 2363075251 OBC_OUTPUT_CURRENT "OBC高压侧电流";
CM_ SG_ 2363075251 ERRORFLAG "OBC故障码";
CM_ SG_ 2363075251 CC_STATUS "CC状态
1: No_Connect
2: HalfConnected
3: ACConnected
4: DisChgCcConnected
5: ConnectedFailure";
CM_ SG_ 2363075251 OUTPUTRELAYSTATUS "输出继电器状态
0: OPEN
1: CLOSE";
CM_ SG_ 2363075252 CPDUTYCYCLE "CP占空比";
CM_ SG_ 2363075252 CHARGEPORTTEMP2 "充电口温度2";
CM_ SG_ 2363075252 CHARGEPORTTEMP1 "充电口温度1";
CM_ SG_ 2363075252 OBCINPUTVOLTAGE "AC电压";
CM_ SG_ 2363075252 PFCVOLTAGE "PFC电压";
CM_ SG_ 2363075253 OBCINPUTCURRENT "AC电流";
CM_ SG_ 2363075253 CHARGEPILELIMITCURRENT "充电设备允许最大电流";
CM_ SG_ 2363075253 BATTERYVOLTAGE "电池电压";
CM_ SG_ 2363075254 OBC_F_DCDCHGMID_REQ "0: No lighting request
1: Lighting request";
CM_ SG_ 2363075254 OBC_F_ACDCHGMID_REQ "0: No lighting request
1: Lighting request";
CM_ SG_ 2363075254 OBC_F_DCCHGMID_REQ "0: No lighting request
1: Lighting request";
CM_ SG_ 2363075254 OBC_F_ACCHGMID_REQ "0: No lighting request
1: Lighting request";
CM_ SG_ 2363075254 OBC_SOFTWAREVERSION "软件版本号";
CM_ SG_ 2363075254 OBC_HARDWAREVERSION "硬件版本号";
CM_ SG_ 2363075254 DC_CHARGE_NEGA_RELY_STATE "快充负极接触器状态";
CM_ SG_ 2363075254 DC_CHARGE_POSI_RELY_STATE "快充正极接触器状态";
CM_ SG_ 2363075254 CP_STATUS "CP状态";
CM_ SG_ 2363075254 CHG_STFSADCCHG "快充时FSA要求";
CM_ SG_ 2363075254 CHG_STFSAACCHG "AC充电时FSA要求";
CM_ SG_ 2363075254 CHG_STFSAACDCHG "逆变时FSA要求";
CM_ SG_ 2363075255 CC_RESISTANCE "CC阻值";
CM_ SG_ 2363075255 DC_CHARGE_IP_VOLT "快充侧电压";
CM_ SG_ 2363075255 CHGR_LICMDSTP "OBC充电低负载状态";
CM_ SG_ 2363075255 S2STATUS "S2状态";
CM_ SG_ 2363075255 CANIP_OBC_INTER_OVERTEMP "OBC过温";
CM_ SG_ 2363075255 CANIP_BOOL_OBC_IP_UNDERVOLT "AC欠压";
CM_ SG_ 2363075255 CANIP_BOOL_OBC_IP_OVERVOLT "AC过压";
CM_ SG_ 2363075255 CANIP_BOOL_OBC_PFC_OVERVOLT "PFC过压";
CM_ SG_ 2363075255 CANIP_BOOL_CHARSEATTEMPNOTFIND "充电口温度传感器异常";
CM_ SG_ 2363075255 OBC_POWERSYS_REQ "OBC警告灯请求";
CM_ SG_ 2363075255 OBC_12V_WARN_MID_REQ "12v警告灯请求 ";
CM_ SG_ 2363075255 CANIP_AC_CHARGING_PILE_ERROR "充电设备故障";
CM_ SG_ 2363075255 CANIP_BOOL_OBC_OP_OVERCURRENT "高压侧过流";
CM_ SG_ 2363075255 CANIP_BOOL_OBC_OP_UNDERVOLT "高压侧欠压";
CM_ SG_ 2363075255 CANIP_BOOL_OBC_OP_OVERVOLT "高压侧过压";
CM_ SG_ 2363075255 CANIP_BOOL_CHECKSUMERROR "CHECKSUM错误";
CM_ SG_ 2363075255 CANIP_BOOL_ACCHAR_SEAT_OVERTEMP "充电口过温";
CM_ SG_ 2363075256 DCDCOPERATINGMODE "DC工作模式
0-初始化 
1-待机（初始化完成）    
2-工作 
3-一级故障 （仅报警、无特殊操作）
4-二级故障（关闭输出，上报故障）";
CM_ SG_ 2363075256 CHG_F_WVINCLDNIMA "VIN判断状态";
CM_ SG_ 2363075256 CHG_F_CHGCNE "充电口状态(有无枪)仅适用于欧标";
CM_ SG_ 2363075256 CHG_F_LEAKDTCTUNITFAIL "漏电检测异常";
CM_ SG_ 2363075256 CHG_F_V2L_ONLYFAIL "可充电不可逆变故障状态";
CM_ SG_ 2363075256 CHG_F_V2L_LEAKDETECT "漏电检测状态";
CM_ SG_ 2363075256 CHG_F_V2L_OVERLOAD "逆变过功率";
CM_ SG_ 1691 CHG_OBS_UPDATE "OBS状态";
CM_ SG_ 1691 CHG_DTC_UPDATE "DTC状态";
CM_ SG_ 1691 CHG_FREEZE_UPDATE "FreezeData状态";
VAL_ 559 BATT_DVINH_22F 0 " DV启动" 1 " DV停止" ;
VAL_ 559 BATT_IGSW_22F 1 " IGSW_ON" 0 " IGSW_OFF" ;
VAL_ 2209174878 CC2STATUS 1 "DC_Charge" 0 "No_DC_Charge" ;
VAL_ 2209174878 DC_CHARGE_NEGA_RELAY_CMD 0 "OPEN" 1 "CLOSE" ;
VAL_ 2209174878 DC_CHARGE_POSI_RELAY_CMD 0 "OPEN" 1 "CLOSE" ;
VAL_ 381 ENG_CLR_REQ_VIN 0 "No" 1 "Yes" ;
VAL_ 287 ENG_CLR_CMD_INH 0 "No" 1 "Yes" ;
VAL_ 287 ENG_SYSTEM_READY 0 "No" 1 "Yes" ;
VAL_ 530 MG_BATT_CHARGING 1 " Charging" 0 " Not charging" ;
VAL_ 530 MG_POWER_GENERATION_UNAVAILABLE 1 " Power generation unavailable" 0 " Power generation available" ;
VAL_ 2209174862 ACCHARALLOW 0 "無効(无效)" 1 "有効(有效)" ;
VAL_ 2209174862 ACDISCHARALLOW 0 "無効(无效)" 1 "有効(有效)" ;
VAL_ 903 TM_SHFT_IN_PARKING 0 "No" 1 "Yes" ;
VAL_ 903 TM_PPOSFAIL 0 "No" 1 "Yes" ;
VAL_ 903 TM_PPOSAVAL 0 "No" 1 "Yes" ;
VAL_ 2363075132 ICM_EN_CNELKFLD 0 " Undecided" 1 " Allow detection" ;
VAL_ 2363075203 ICM_CHG_WUACPT_STATE 0 " No request" 1 " activation request" 2 " deactivation request" ;
VAL_ 2363075203 ICM_COMMUCMD 0 " No request" 1 " activation request" 2 " deactivation request" ;
VAL_ 2363075203 ICM_CNELOCKCMD 0 " No request" 1 " Lock request" 2 " Unlock request" ;
VAL_ 558 DDC12V_CHG_LAMP 0 "No" 1 "Yes" ;
VAL_ 558 DDC12V_VO_LV 0 "No" 1 "Yes" ;
VAL_ 558 DDC12V_DV_ERR 0 "Normal" 1 "Error" ;
VAL_ 558 DDC12V_OT_1 0 "No" 1 "Yes" ;
VAL_ 558 DDC12V_OC 0 "Normal" 1 "Error" ;
VAL_ 558 DDC12V_TS_ERR 0 "Normal" 1 "Error" ;
VAL_ 558 DDC12V_RX_ERR 0 "Normal" 1 "Error" ;
VAL_ 558 DDC12V_CAN_NON 0 "Normal" 1 "Error" ;
VAL_ 558 DDC12V_DV_INH 0 "Normal" 1 "Stop" ;
VAL_ 558 DDC12V_IG_LV 0 "Normal" 1 "Warming" ;
VAL_ 558 DDC12V_IG_UV 0 "Normal" 1 "Warming" ;
VAL_ 558 DDC12V_OT_2 0 "Normal" 1 "Error" ;
VAL_ 558 DDC12V_VO_OV 0 "Normal" 1 "Error" ;
VAL_ 558 DDC12V_VI_OV 0 "Normal" 1 "Error" ;
VAL_ 558 DDC12V_VI_LV 0 "Normal" 1 "Warming" ;
VAL_ 2363075187 CHG_WUREQ_STATE 0 " No request" 1 " activation request" 2 " deactivation request" ;
VAL_ 2363075187 CHG_NMSTOP_REQ 0 " before judgement" 1 " working" 2 " SLEEP ready" ;
VAL_ 2363075128 CHGR_STCNELK 0 " Undecided" 1 " Unlocked" 2 " Locked" ;
VAL_ 2363075128 CHGR_STCNELKFL 0 " Undecided" 1 " Lock mistake" 2 " Lock impossible failure" 3 " Unlock impossible failure" ;
VAL_ 2363075251 OBCFAULTLEVEL 0 " No fault" 1 " Level-1 fault" 2 " Level-2 fault" ;
VAL_ 2363075251 CDU_STATE 0 " CDU_Init_State" 1 " CDU_HandleCheck_State" 2 " AC_CHG_Standby_State" 3 " AC_CHG_Running_State" 4 " AC_CHG_RecvFault_State" 5 " AC_CHG_UnrecvFault_State" 6 " DC_CHG_Standby_State" 7 " DISCHG_Standby_State" 8 " DISCHG_Running_State" 9 " DISCHG_RecvFault_State" 10 " DISCHG_UnrecvFault_State" 11 " CDU_Sleep_State" ;
VAL_ 2363075251 CC_STATUS 1 " No_Connect" 2 " HalfConnected" 3 " ACConnected" 4 " DisChgCcConnected" 5 " ConnectedFailure" ;
VAL_ 2363075251 OUTPUTRELAYSTATUS 0 " OPEN" 1 " CLOSE" ;
VAL_ 2363075254 CHG_STFSADCDCHG 0 " No FSA request" 1 " Power Limit Discharging" 3 " DC Discharging Stop request" ;
VAL_ 2363075254 DC_CHARGE_NEGA_RELY_STATE 0 "初始化" 1 "断开" 2 "闭合" 3 "粘连" 4 "无法闭合" ;
VAL_ 2363075254 DC_CHARGE_POSI_RELY_STATE 0 "初始化" 1 "断开" 2 "闭合" 3 "粘连" 4 "无法闭合" ;
VAL_ 2363075254 CP_STATUS 0 " CP_No" 1 " CP_Nomal" 2 " CP_Abnomal" 3 " Reserve" ;
VAL_ 2363075254 CHG_STFSADCCHG 0 " No FSA request" 1 " Power Limit Charging" 3 " DC Charging Stop request" ;
VAL_ 2363075254 CHG_STFSAACCHG 0 " No FSA request" 1 " Power Limit Charging" 3 " AC Charging Stop request" ;
VAL_ 2363075254 CHG_STFSAACDCHG 0 " No FSA request" 1 " Power Limit Discharging" 3 " AC Charging Stop request" ;
VAL_ 2363075254 CHG_STFSACHGDR 0 " No FSA request" 1 " Power Limit Discharging" 3 " AC Charging Stop request" ;
VAL_ 2363075255 OBC_12VSTATUS 0 " disable" 1 " enable" ;
VAL_ 2363075255 CHGR_LICMDSTP 0 "Normal" 1 "Stopping" ;
VAL_ 2363075255 S2STATUS 0 " OPEN" 1 " CLOSE" ;
VAL_ 2363075255 CANIP_OBC_INTER_OVERTEMP 0 " Normal" 1 " Error" ;
VAL_ 2363075255 CANIP_BOOL_OBC_IP_UNDERVOLT 0 " Normal" 1 " Error" ;
VAL_ 2363075255 CANIP_BOOL_OBC_IP_OVERVOLT 0 " Normal" 1 " Error" ;
VAL_ 2363075255 CANIP_BOOL_OBC_PFC_OVERVOLT 0 " Normal" 1 " Error" ;
VAL_ 2363075255 CANIP_BOOL_CHARSEATTEMPNOTFIND 0 " Normal" 1 " Error" ;
VAL_ 2363075255 OBC_POWERSYS_REQ 0 " No lighting request" 1 " Lighting request" ;
VAL_ 2363075255 OBC_12V_WARN_MID_REQ 0 " No lighting request" 1 " Lighting request" ;
VAL_ 2363075255 CANIP_AC_CHARGING_PILE_ERROR 0 " Normal" 1 " Error" ;
VAL_ 2363075255 CANIP_BOOL_OBC_OP_OVERCURRENT 0 " Normal" 1 " Error" ;
VAL_ 2363075255 CANIP_BOOL_OBC_OP_UNDERVOLT 0 " Normal" 1 " Error" ;
VAL_ 2363075255 CANIP_BOOL_OBC_OP_OVERVOLT 0 " Normal" 1 " Error" ;
VAL_ 2363075255 CANIP_BOOL_CHECKSUMERROR 0 " Normal" 1 " Error" ;
VAL_ 2363075255 CANIP_BOOL_ACCHAR_SEAT_OVERTEMP 0 " Normal" 1 " Error" ;
VAL_ 2363075256 DCDCOPERATINGMODE 0 "初始化 " 1 "待机（初始化完成）    " 2 "工作 " 3 "一级故障 （仅报警、无特殊操作）" 4 "二级故障（关闭输出，上报故障）" ;
VAL_ 2363075256 CHG_F_WVINCLDNIMA 1 " VIN登録時クリア完了" 0 " 未確定" ;
VAL_ 2363075256 CHG_F_CHGCNE 1 " 未確定" 0 " AC充給電コネクタ非嵌合" ;
VAL_ 2363075256 CHG_F_LEAKDTCTUNITFAIL 1 " VIN登録時クリア完了" 0 " 未確定" ;
VAL_ 2363075256 CHG_F_V2L_ONLYFAIL 1 " AC充電可能かつAC給電不可異常?故障検知" 0 " 未確定" ;
VAL_ 2363075256 CHG_F_V2L_LEAKDETECT 1 " 漏電検知" 0 " 未確定" ;
VAL_ 2363075256 CHG_F_V2L_OVERLOAD 1 " AC給電中過負荷接続" 0 " 未確定" ;
VAL_ 1691 CHG_OBS_UPDATE 0 " DTC無し" 1 " DTC有り" 2 " DTC有り" 3 " DTC有り" ;
VAL_ 1691 CHG_DTC_UPDATE 0 " OBS無し" 1 " OBS有り" 2 " OBS有り" 3 " OBS有り" ;
VAL_ 1691 CHG_FREEZE_UPDATE 0 " FreezeData無し" 1 " FreezeData有り" 2 " FreezeData有り" 3 " FreezeData有り" ;
